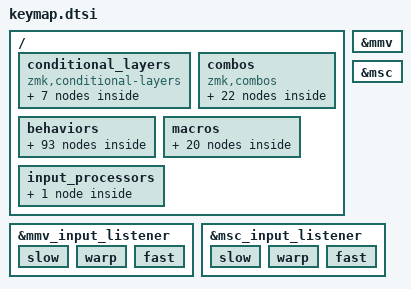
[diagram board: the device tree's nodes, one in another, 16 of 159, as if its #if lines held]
//////////////////////////////////////////////////////////////////////////////
//
// Kinesis Advantage 360 Pro - Keymap Behaviors, Combos, and Macros
//
// Ported from sunaku's Glove80 keymap v52 "Glorious Engrammer"
// https://github.com/sunaku/glove80-keymaps
//
// This file is #include'd by adv360.keymap after positions.h and layer defs.
// LEFT_HAND_KEYS, RIGHT_HAND_KEYS, and *_KEY aliases are in positions.h.
//
//////////////////////////////////////////////////////////////////////////////

//
// NOTE: Use the many #define settings below to customize this keymap!
//
#ifndef OPERATING_SYSTEM
  #define OPERATING_SYSTEM 'L' // choose 'L'inux, 'M'acOS, or 'W'indows
#endif
#ifndef DIFFICULTY_LEVEL
  #define DIFFICULTY_LEVEL  0  // 0:custom, 1:easy -> 5:hard (see below)
#endif
#define ENABLE_MOUSE_KEYS    // requires CONFIG_ZMK_POINTING=y in defconfig
//#define ENFORCE_BILATERAL  // cancels single-handed home row mod+tap
//#define SPACE_FORGIVENESS  // allow lingering taps on the space bar
//#define THUMB_FORGIVENESS  // allow lingering taps on the thumb keys
//#define SHIFT_FORGIVENESS  // requires v24.08-beta or newer firmware
//#define NATURAL_SCROLLING  // supports "natural scrolling" in macOS
//#define WORLD_USE_COMPOSE  // use native Compose in place of Unicode
//#define WORLD_HOST_AZERTY  // host computer is set to AZERTY locale
//#define WORLD_SHIFT_NUMBER // apply Shift to type number row digits
// TIP: Add more setting overrides here instead of editing them below.

//
// OPERATING_SYSTEM defines which operating system you intend to use
// with this keymap, because shortcuts vary across operating systems.
//
#if OPERATING_SYSTEM == 'M'
  #define _C      LG
  #define _A_TAB  LGUI
  #define _G_TAB  LALT
  #define _REDO   LG(LS(Z))
  #define _POWER  K_POWER
  #define _WORD   LA
  #define _HOME   LG(LEFT)
  #define _END    LG(RIGHT)
  #define _EMOJI  LG(LC(SPACE))
  #define _FILES  LS(LA(M))
  #define _GLOBE  GLOBE
#else
  #define _C      LC
  #define _A_TAB  LALT
  #define _G_TAB  LGUI
  #define _REDO   LC(Y)
  #define _POWER  C_POWER
  #define _WORD   LC
  #define _HOME   HOME
  #define _END    END
  #define _EMOJI  LG(DOT)
  #define _FILES  LG(E)
  #define _GLOBE  LGUI
#endif
#define _SLEEP      C_SLEEP
#if OPERATING_SYSTEM == 'W'
  #define _LOCK   LG(L)
#elif OPERATING_SYSTEM == 'M'
  #define _LOCK   _C(LC(Q))
#elif OPERATING_SYSTEM == 'L'
  #define _LOCK   K_LOCK
#endif
#define _UNDO       _C(Z)
#define _CUT        _C(X)
#define _COPY       _C(C)
#define _PASTE      _C(V)
#define _FIND       _C(F)
#define _FIND_NEXT  _C(G)
#define _FIND_PREV  _C(LS(G))

//
// QWERTY base layer alpha key definitions
//
#if defined(LAYER_QWERTY) && LAYER_QWERTY == 0
  #define KEY_LH_C6R1 0
  #define KEY_LH_C5R1 0
  #define KEY_LH_C4R1 0
  #define KEY_LH_C3R1 0
  #define KEY_LH_C2R1 0
  #define KEY_RH_C2R1 0
  #define KEY_RH_C3R1 0
  #define KEY_RH_C4R1 0
  #define KEY_RH_C5R1 0
  #define KEY_RH_C6R1 0
  #define KEY_LH_C6R2 0
  #define KEY_LH_C5R2 N1
  #define KEY_LH_C4R2 N2
  #define KEY_LH_C3R2 N3
  #define KEY_LH_C2R2 N4
  #define KEY_LH_C1R2 N5
  #define KEY_RH_C1R2 N6
  #define KEY_RH_C2R2 N7
  #define KEY_RH_C3R2 N8
  #define KEY_RH_C4R2 N9
  #define KEY_RH_C5R2 N0
  #define KEY_RH_C6R2 0
  #define KEY_LH_C6R3 0
  #define KEY_LH_C5R3 Q
  #define KEY_LH_C4R3 W
  #define KEY_LH_C3R3 E
  #define KEY_LH_C2R3 R
  #define KEY_LH_C1R3 T
  #define KEY_RH_C1R3 Y
  #define KEY_RH_C2R3 U
  #define KEY_RH_C3R3 I
  #define KEY_RH_C4R3 O
  #define KEY_RH_C5R3 P
  #define KEY_RH_C6R3 MINUS
  #define KEY_LH_C6R4 EQUAL
  #define KEY_LH_C5R4 A
  #define KEY_LH_C4R4 S
  #define KEY_LH_C3R4 D
  #define KEY_LH_C2R4 F
  #define KEY_LH_C1R4 G
  #define KEY_RH_C1R4 H
  #define KEY_RH_C2R4 J
  #define KEY_RH_C3R4 K
  #define KEY_RH_C4R4 L
  #define KEY_RH_C5R4 SEMI
  #define KEY_RH_C6R4 SQT
  #define KEY_LH_C6R5 LSFT
  #define KEY_LH_C5R5 Z
  #define KEY_LH_C4R5 X
  #define KEY_LH_C3R5 C
  #define KEY_LH_C2R5 V
  #define KEY_LH_C1R5 B
  #define KEY_LH_T1 ESC
  #define LAY_LH_T1 LAYER_Function
  #define KEY_LH_T2 0
  #define LAY_LH_T2 LAYER_Lower
  #define KEY_LH_T3 PG_UP
  #define KEY_RH_T3 0
  #define KEY_RH_T2 INSERT
  #define LAY_RH_T2 LAYER_Lower
  #define KEY_RH_T1 ENTER
  #define LAY_RH_T1 LAYER_System
  #define KEY_RH_C1R5 N
  #define KEY_RH_C2R5 M
  #define KEY_RH_C3R5 COMMA
  #define KEY_RH_C4R5 DOT
  #define KEY_RH_C5R5 FSLH
  #define KEY_RH_C6R5 RSFT
  #define KEY_LH_C6R6 0
  #define KEY_LH_C5R6 BSLH
  #define KEY_LH_C4R6 LPAR
  #define KEY_LH_C3R6 RPAR
  #define KEY_LH_C2R6 LSFT
  #define LAY_LH_C2R6 LAYER_Emoji
  #define KEY_LH_T4 BACKSPACE
  #define LAY_LH_T4 LAYER_Cursor
  #define KEY_LH_T5 DELETE
  #define LAY_LH_T5 LAYER_Number
  #define KEY_LH_T6 PG_DN
  #define KEY_RH_T6 0
  #define KEY_RH_T5 TAB
  #define LAY_RH_T5 LAYER_Mouse
  #define KEY_RH_T4 SPACE
  #define LAY_RH_T4 LAYER_Symbol
  #define KEY_RH_C2R6 RSFT
  #define LAY_RH_C2R6 LAYER_World
  #define KEY_RH_C3R6 LBKT
  #define KEY_RH_C4R6 RBKT
  #define KEY_RH_C5R6 GRAVE
  #define KEY_RH_C6R6 0
#endif

/ {
conditional_layers {
  compatible = "zmk,conditional-layers";
  #ifdef LAYER_macOS
  #ifdef LAYER_macOS_left
    #ifdef LAYER_Cursor
    if_LAYER_Cursor_then_LAYER_macOS_left {
      if-layers = <LAYER_macOS LAYER_Cursor>;
      then-layer = <LAYER_macOS_left>;
    };
    #endif
    #ifdef LAYER_Number
    if_LAYER_Number_then_LAYER_macOS_left {
      if-layers = <LAYER_macOS LAYER_Number>;
      then-layer = <LAYER_macOS_left>;
    };
    #endif
    #ifdef LAYER_Function
    if_LAYER_Function_then_LAYER_macOS_left {
      if-layers = <LAYER_macOS LAYER_Function>;
      then-layer = <LAYER_macOS_left>;
    };
    #endif
  #endif
  #ifdef LAYER_macOS_right
    #ifdef LAYER_Symbol
    if_LAYER_Symbol_then_LAYER_macOS_right {
      if-layers = <LAYER_macOS LAYER_Symbol>;
      then-layer = <LAYER_macOS_right>;
    };
    #endif
    #ifdef LAYER_Mouse
    if_LAYER_Mouse_then_LAYER_macOS_right {
      if-layers = <LAYER_macOS LAYER_Mouse>;
      then-layer = <LAYER_macOS_right>;
    };
    #endif
    #ifdef LAYER_System
    if_LAYER_System_then_LAYER_macOS_right {
      if-layers = <LAYER_macOS LAYER_System>;
      then-layer = <LAYER_macOS_right>;
    };
    #endif
  #endif
  #ifdef LAYER_macOS_lower
    #ifdef LAYER_Lower
    if_LAYER_Lower_then_LAYER_macOS_lower {
      if-layers = <LAYER_macOS LAYER_Lower>;
      then-layer = <LAYER_macOS_lower>;
    };
    #endif
  #endif
  #endif
};

combos {
  compatible = "zmk,combos";

  //
  // COMBO_FIRING_DECAY defines how much time you have left (milliseconds)
  // after pressing the first key in a ZMK combo to finish the whole chord.
  //
  #ifndef COMBO_FIRING_DECAY
  #define COMBO_FIRING_DECAY 50
  #endif

  //
  // SHIFT_FIRING_DECAY defines how much time you have left (milliseconds)
  // after pressing the first key in the one-shot sticky shift ZMK combo
  // (on index finger home + thumb cluster T1) to finish the whole chord.
  //
  #ifndef SHIFT_FIRING_DECAY
  #define SHIFT_FIRING_DECAY 50
  #endif

  // T2+T3

  combo_sticky_globe_left {
    timeout-ms = <COMBO_FIRING_DECAY>;
    key-positions = <POS_LH_T2 POS_LH_T3>;
    bindings = <&sk _GLOBE>;
    layers = <0 1>;
  };

  combo_sticky_globe_right {
    timeout-ms = <COMBO_FIRING_DECAY>;
    key-positions = <POS_RH_T2 POS_RH_T3>;
    bindings = <&sk _GLOBE>;
    layers = <0 1>;
  };

  // T1+T2

  combo_sticky_altgr_left {
    timeout-ms = <COMBO_FIRING_DECAY>;
    key-positions = <POS_LH_T1 POS_LH_T2>;
    bindings = <&sk RALT>;
    layers = <0 1>;
  };

  combo_sticky_altgr_right {
    timeout-ms = <COMBO_FIRING_DECAY>;
    key-positions = <POS_RH_T1 POS_RH_T2>;
    bindings = <&sk RALT>;
    layers = <0 1>;
  };

  // T1+T4
  #if defined(_A_TAB) && defined(LAYER_Cursor)
  combo_alt_tab_switcher_left {
    timeout-ms = <COMBO_FIRING_DECAY>;
    key-positions = <POS_LH_T1 POS_LH_T4>;
    bindings = <&mod_tab_chord _A_TAB LAYER_Cursor>;
    layers = <0 1>;
  };
  #endif

  combo_hyper_GACS_right {
    timeout-ms = <COMBO_FIRING_DECAY>;
    key-positions = <POS_RH_T1 POS_RH_T4>;
    bindings = <&kp LG(LA(LC(LSHFT)))>;
    layers = <0 1>;
  };

  // T3+T6
  #if defined(_G_TAB) && defined(LAYER_Cursor)
  combo_win_tab_switcher_left {
    timeout-ms = <COMBO_FIRING_DECAY>;
    key-positions = <POS_LH_T3 POS_LH_T6>;
    bindings = <&mod_tab_chord _G_TAB LAYER_Cursor>;
    layers = <0 1>;
  };
  #endif

  combo_turbo_CS_right {
    timeout-ms = <COMBO_FIRING_DECAY>;
    key-positions = <POS_RH_T3 POS_RH_T6>;
    bindings = <&kp LC(LSHFT)>;
    layers = <0 1>;
  };

  // T2+T5

  combo_ctrl_tab_switcher_left {
    timeout-ms = <COMBO_FIRING_DECAY>;
    key-positions = <POS_LH_T2 POS_LH_T5>;
    bindings = <&mod_tab_chord LCTL LAYER_Cursor>;
    layers = <0 1>;
  };

  combo_meh_ACS_right {
    timeout-ms = <COMBO_FIRING_DECAY>;
    key-positions = <POS_RH_T2 POS_RH_T5>;
    bindings = <&kp LA(LC(LSHFT))>;
    layers = <0 1>;
  };

  // T1+T5

  combo_sticky_shift_left {
    timeout-ms = <SHIFT_FIRING_DECAY>;
    key-positions = <POS_LH_T1 POS_LH_T5>;
    bindings = <&sticky_key_modtap LSFT LSFT>;
    layers = <0 1 2>;
  };

  combo_sticky_shift_right {
    timeout-ms = <SHIFT_FIRING_DECAY>;
    key-positions = <POS_RH_T1 POS_RH_T5>;
    bindings = <&sticky_key_modtap RSFT RSFT>;
    layers = <0 1 2>;
  };

  // T4+T5

  combo_caps_word_left {
    timeout-ms = <COMBO_FIRING_DECAY>;
    key-positions = <POS_LH_T4 POS_LH_T5>;
    bindings = <&caps_word>;
    layers = <0 1 2>;
  };

  combo_caps_word_right {
    timeout-ms = <COMBO_FIRING_DECAY>;
    key-positions = <POS_RH_T4 POS_RH_T5>;
    bindings = <&caps_word>;
    layers = <0 1 2>;
  };

  // T2+T6

  combo_caps_lock_left {
    timeout-ms = <COMBO_FIRING_DECAY>;
    key-positions = <POS_LH_T2 POS_LH_T6>;
    bindings = <&kp CAPSLOCK>;
    layers = <0 1 2>;
  };

  combo_caps_lock_right {
    timeout-ms = <COMBO_FIRING_DECAY>;
    key-positions = <POS_RH_T2 POS_RH_T6>;
    bindings = <&kp CAPSLOCK>;
    layers = <0 1 2>;
  };

  // T5+T6
  #ifdef LAYER_Typing
  combo_typing_layer_access_left {
    timeout-ms = <COMBO_FIRING_DECAY>;
    key-positions = <POS_LH_T5 POS_LH_T6>;
    bindings = <&mo LAYER_Typing>;
    layers = <0 1 2 3 4 5 6 7 8 9 10 11 12 13 14 15 16 17 18 19 20 21 22>;
  };

  combo_typing_layer_access_right {
    timeout-ms = <COMBO_FIRING_DECAY>;
    key-positions = <POS_RH_T5 POS_RH_T6>;
    bindings = <&mo LAYER_Typing>;
    layers = <0 1 2 3 4 5 6 7 8 9 10 11 12 13 14 15 16 17 18 19 20 21 22>;
  };
  #endif

  // C1R5+C2R6
  #ifdef LAYER_Gaming
  combo_gaming_layer_toggle {
    timeout-ms = <COMBO_FIRING_DECAY>;
    key-positions = <POS_LH_C1R5 POS_LH_C2R6>;
    bindings = <&tog LAYER_Gaming>;
    layers = <0 LAYER_Gaming
      #ifdef LAYER_macOS
      LAYER_macOS
      #endif
    >;
  };
  #endif
  #ifdef LAYER_Typing
  combo_typing_layer_toggle {
    timeout-ms = <COMBO_FIRING_DECAY>;
    key-positions = <POS_RH_C1R5 POS_RH_C2R6>;
    bindings = <&tog LAYER_Typing>;
    layers = <0 LAYER_Typing
      #ifdef LAYER_macOS
      LAYER_macOS
      #endif
    >;
  };
  #endif

  // T1+T2+T3

  combo_sticky_base_layer_reset_left {
    timeout-ms = <COMBO_FIRING_DECAY>;
    key-positions = <POS_LH_T1 POS_LH_T2 POS_LH_T3>;
    bindings = <&to 0>;
    layers = <0 1 2 3 4 5 6 7 8 9 10 11 12 13 14 15 16 17 18 19 20 21 22>;
  };

  combo_sticky_base_layer_reset_right {
    timeout-ms = <COMBO_FIRING_DECAY>;
    key-positions = <POS_RH_T1 POS_RH_T2 POS_RH_T3>;
    bindings = <&to 0>;
    layers = <0 1 2 3 4 5 6 7 8 9 10 11 12 13 14 15 16 17 18 19 20 21 22>;
  };

};

behaviors {

  //////////////////////////////////////////////////////////////////////////
  //
  // Miryoku layers and home row mods (ported from my QMK endgame)
  // - https://sunaku.github.io/home-row-mods.html#porting-to-zmk
  // - https://github.com/urob/zmk-config#timeless-homerow-mods
  //
  //////////////////////////////////////////////////////////////////////////

  //
  // DIFFICULTY_LEVEL specifies your level of expertise with this keymap.
  // It's meant to help newcomers gradually work their way up to mastery.
  //
  // #define DIFFICULTY_LEVEL 1 // novice (500ms)
  // #define DIFFICULTY_LEVEL 2 // slower (400ms)
  // #define DIFFICULTY_LEVEL 3 // normal (300ms)
  // #define DIFFICULTY_LEVEL 4 // faster (200ms)
  // #define DIFFICULTY_LEVEL 5 // expert (100ms)
  //
  // You can disable this setting by omitting it or assigning a `0` zero,
  // in which case it will default to my personal set of time thresholds.
  //
  // #define DIFFICULTY_LEVEL 0 // sunaku (150ms)
  //
  // No matter what difficulty level you choose, you can always override
  // any settings in this keymap at the beginning of this configuration.
  //
  #ifdef DIFFICULTY_LEVEL
    #if DIFFICULTY_LEVEL > 0 && DIFFICULTY_LEVEL < 6
      #ifndef TAPPING_RESOLUTION
        #define TAPPING_RESOLUTION ((6 - DIFFICULTY_LEVEL) * 100)
      #endif
    #endif
  #endif

  //
  // TAPPING_RESOLUTION specifies the maximum speed at which the keyboard
  // confuses your taps as being holds when you type on home row mod keys.
  // When you lower this value, the same confusion should still occur; but
  // when you raise this value, you should be able to type normally again.
  //
  #ifndef TAPPING_RESOLUTION
  #define TAPPING_RESOLUTION 150
  #endif

  //
  // ENFORCE_BILATERAL cancels out single-handed home row mods activation by
  // releasing any currently pressed mods and replacing them with plain taps.
  //
  // NOTE: You may still encounter "flashing mods" where an operating system
  // action is triggered by the release of mods, such as LGUI which launches
  // the Windows Start Menu and LALT which opens the Microsoft Office Ribbon.
  //
  //#define ENFORCE_BILATERAL

  //
  // SHIFT_FORGIVENESS taps when home row shift is merely held and released,
  // without any other key having been tapped while the shift was held down.
  // For example, suppose you hold a home row shift key and, before pressing
  // another key, you suddenly decide that you don't want the shift anymore:
  //
  // <1> If this setting is enabled, the underlying tap behavior is triggered
  //     to type a single character when you release that home row shift key.
  //
  // <2> Otherwise, nothing happens when you release that home row shift key.
  //
  // This requires the "hold-while-undecided" ZMK feature in a beta firmware:
  // please select "v24.08-beta1" or newer from the drop-down menu located at
  // Glove80 Layout Editor > Settings > Advanced Settings > Firmware Version.
  //
  // CAUTION: This can interfere with mod-click mouse usage where you hold a
  // home row shift key and perform mouse actions (move, click, drag & drop):
  // when you release that home row shift key, its underlying character would
  // be typed, potentially triggering an unexpected action on your selection!
  // To prevent the underlying character from being typed, press another key
  // (such as a dedicated shift key, a neighboring home row mod key, or even
  // a layer access key) before you release the original home row shift key.
  //
  // NOTE: You may potentially encounter "flashing mods" where an application
  // or operating system action is triggered by a standalone tap of a shift,
  // but this is unlikely as people regularly tap shift without consequence.
  //
  //#define SHIFT_FORGIVENESS

  //
  // THUMB_FORGIVENESS taps when a thumb layer access key is merely held and
  // released, without any other key having been tapped while thumb was held.
  // For example, suppose you hold the cursor layer key and, before pressing
  // another key, you suddenly decide that you don't want the layer anymore:
  //
  // <1> If this setting is enabled, the underlying tap behavior is triggered
  //     to type a single character when you release that layer access key.
  //
  // <2> Otherwise, nothing happens when you release that layer access key.
  //
  // NOTE: This setting interferes with (and effectively disables) per-key
  // RGB indicators (PR30) for layers accessed via thumb layer access keys.
  //
  //#define THUMB_FORGIVENESS

  //
  // SPACE_FORGIVENESS taps when the symbol layer access key is merely held
  // and released, without any symbol been tapped while the access was held.
  // For example, suppose you hold the symbol layer key and, before pressing
  // another key, you suddenly decide that you don't want the layer anymore:
  //
  // <1> If this setting is enabled, the underlying tap behavior is triggered
  //     to type a single character when you release that layer access key.
  //
  // <2> Otherwise, nothing happens when you release that layer access key.
  //
  // NOTE: This setting interferes with (and effectively disables) per-key
  // RGB indicators (PR30) for layers accessed via thumb layer access keys.
  //
  //#define SPACE_FORGIVENESS
  #ifdef SPACE_FORGIVENESS
  #ifndef SPACE_HOLDING_TYPE
  #define SPACE_HOLDING_TYPE "tap-preferred"
  #endif
  #endif

  //
  // The *_FINGER_MOD specify which modifiers are used by home row mod keys.
  // Here, we use Miryoku's "GACS" (Win, Alt, Ctrl, Shift) order by default,
  // unless OPERATING_SYSTEM is macOS, in which case Win & Ctrl are swapped,
  // unless MACOS_USE_GACS is also defined to suppress that Win & Ctrl swap.
  //
  #ifndef PINKY_FINGER_MOD
    #if OPERATING_SYSTEM == 'M' && !defined(MACOS_USE_GACS)
      #define PINKY_FINGER_MOD LCTL
    #else
      #define PINKY_FINGER_MOD LGUI
    #endif
  #endif
  #ifndef RINGY_FINGER_MOD
  #define RINGY_FINGER_MOD LALT
  #endif
  #ifndef MIDDY_FINGER_MOD
    #if OPERATING_SYSTEM == 'M' && !defined(MACOS_USE_GACS)
      #define MIDDY_FINGER_MOD LGUI
    #else
      #define MIDDY_FINGER_MOD LCTL
    #endif
  #endif
  #ifndef INDEX_FINGER_MOD
  #define INDEX_FINGER_MOD LSFT
  #endif
  //
  // The following settings let you configure mods individually, per finger:
  //
  #ifndef LEFT_PINKY_MOD
  #define LEFT_PINKY_MOD PINKY_FINGER_MOD
  #endif
  #ifndef RIGHT_PINKY_MOD
  #define RIGHT_PINKY_MOD PINKY_FINGER_MOD
  #endif
  #ifndef LEFT_RINGY_MOD
  #define LEFT_RINGY_MOD RINGY_FINGER_MOD
  #endif
  #ifndef RIGHT_RINGY_MOD
  #define RIGHT_RINGY_MOD RINGY_FINGER_MOD
  #endif
  #ifndef LEFT_MIDDY_MOD
  #define LEFT_MIDDY_MOD MIDDY_FINGER_MOD
  #endif
  #ifndef RIGHT_MIDDY_MOD
  #define RIGHT_MIDDY_MOD MIDDY_FINGER_MOD
  #endif
  #ifndef LEFT_INDEX_MOD
  #define LEFT_INDEX_MOD INDEX_FINGER_MOD
  #endif
  #ifndef RIGHT_INDEX_MOD
  #define RIGHT_INDEX_MOD INDEX_FINGER_MOD
  #endif

  //
  // HOMEY_HOLDING_TYPE defines the flavor of ZMK hold-tap behavior to use
  // for the pinky, ring, and middle fingers (which are assigned to Super,
  // Alt, and Ctrl respectively in the Miryoku system) on home row keys.
  //
  #ifndef HOMEY_HOLDING_TYPE
  #define HOMEY_HOLDING_TYPE "tap-preferred"
  #endif

  //
  // HOMEY_HOLDING_TIME defines how long you need to hold (milliseconds)
  // home row mod keys in order to send their modifiers to the computer
  // (i.e. "register" them) for mod-click mouse usage (e.g. Ctrl-Click).
  //
  #ifndef HOMEY_HOLDING_TIME
  #define HOMEY_HOLDING_TIME (TAPPING_RESOLUTION + 90)
  #endif
  #ifndef INDEX_HOLDING_TIME
  #define INDEX_HOLDING_TIME (TAPPING_RESOLUTION + 30)
  #endif
  #ifndef MIDDY_HOLDING_TIME
  #define MIDDY_HOLDING_TIME (TAPPING_RESOLUTION + 60)
  #endif
  #ifndef RINGY_HOLDING_TIME
  #define RINGY_HOLDING_TIME (TAPPING_RESOLUTION + 90)
  #endif
  #ifndef PINKY_HOLDING_TIME
  #define PINKY_HOLDING_TIME (TAPPING_RESOLUTION + 120)
  #endif

  //
  // HOMEY_STREAK_DECAY defines how long you need to wait (milliseconds)
  // after typing before you can use home row mods again.  It prevents
  // unintended activation of home row mods when you're actively typing.
  //
  #ifndef HOMEY_STREAK_DECAY
  #define HOMEY_STREAK_DECAY TAPPING_RESOLUTION
  #endif

  //
  // HOMEY_REPEAT_DECAY defines how much time you have left (milliseconds)
  // after tapping a key to hold it again in order to make it auto-repeat.
  //
  #ifndef HOMEY_REPEAT_DECAY
  #define HOMEY_REPEAT_DECAY (TAPPING_RESOLUTION + 150)
  #endif // "tap then hold" for key auto-repeat

  //
  // CHORD_HOLDING_TYPE defines the flavor of ZMK hold-tap behavior to use
  // for chorded home row mods (secondary keypresses in multi-mod chords).
  //
  #ifndef CHORD_HOLDING_TYPE
  #define CHORD_HOLDING_TYPE HOMEY_HOLDING_TYPE
  #endif

  //
  // CHORD_HOLDING_TIME defines how long you need to hold (milliseconds)
  // home row mod keys in order to send their modifiers to the computer
  // (i.e. "register" them) for mod-click mouse usage (e.g. Ctrl-Click).
  // This is specifically for secondary keypresses in multi-mod chords.
  //
  #ifndef CHORD_HOLDING_TIME
  #define CHORD_HOLDING_TIME TAPPING_RESOLUTION
  #endif

  //
  // CHORD_STREAK_DECAY defines how long you need to wait (milliseconds)
  // after typing before you can use home row mods again.  It prevents
  // unintended activation of home row mods when you're actively typing
  // This is specifically for secondary keypresses in multi-mod chords.
  //
  #ifndef CHORD_STREAK_DECAY
  #define CHORD_STREAK_DECAY HOMEY_STREAK_DECAY
  #endif

  //
  // CHORD_REPEAT_DECAY defines how much time you have left (milliseconds)
  // after tapping a key to hold it again in order to make it auto-repeat.
  // This is specifically for secondary keypresses in multi-mod chords.
  //
  #ifndef CHORD_REPEAT_DECAY
  #define CHORD_REPEAT_DECAY HOMEY_REPEAT_DECAY
  #endif

  //
  // INDEX_HOLDING_TYPE defines the flavor of ZMK hold-tap behavior to use
  // for index fingers (which Miryoku assigns to Shift) on home row keys.
  //
  // NOTE: The "tap-preferred" flavor of ZMK hold-tap for index finger keys
  // allows faster activation of the Shift modifier (without having to wait
  // for the modified key to be released as the "balanced" flavor requires).
  //
  #ifndef INDEX_HOLDING_TYPE
  #define INDEX_HOLDING_TYPE "tap-preferred"
  #endif

  //
  // INDEX_STREAK_DECAY defines how long you need to wait (milliseconds)
  // after typing before you can use home row mods again.  It prevents
  // unintended activation of home row mods when you're actively typing.
  //
  #ifndef INDEX_STREAK_DECAY
  #define INDEX_STREAK_DECAY TAPPING_RESOLUTION
  #endif

  //
  // INDEX_REPEAT_DECAY defines how much time you have left (milliseconds)
  // after tapping a key to hold it again in order to make it auto-repeat.
  //
  #ifndef INDEX_REPEAT_DECAY
  #define INDEX_REPEAT_DECAY (TAPPING_RESOLUTION + 150)
  #endif // "tap then hold" for key auto-repeat

  //
  // THUMB_HOLDING_TYPE defines the flavor of ZMK hold-tap behavior to use
  // for the thumbs (which are assigned to 6 layers in the Miryoku system).
  //
  // NOTE: The "balanced" flavor of ZMK hold-tap provides instant modifier
  // activation for the symbol layer (if the tapped symbol key is released
  // while the thumb layer key is still held down) for quicker programming.
  //
  #ifndef THUMB_HOLDING_TYPE
  #define THUMB_HOLDING_TYPE "balanced"
  #endif

  //
  // THUMB_HOLDING_TIME defines how long you need to hold (milliseconds)
  // a thumb key to activate a layer.  Shorter holds are treated as taps.
  //
  #ifndef THUMB_HOLDING_TIME
  #define THUMB_HOLDING_TIME (TAPPING_RESOLUTION + 50)
  #endif

  //
  // THUMB_REPEAT_DECAY defines how much time you have left (milliseconds)
  // after tapping a key to hold it again in order to make it auto-repeat.
  //
  #ifndef THUMB_REPEAT_DECAY
  #define THUMB_REPEAT_DECAY (TAPPING_RESOLUTION + 150)
  #endif // "tap then hold" for key auto-repeat

  //
  // SPACE_HOLDING_TYPE defines the flavor of ZMK hold-tap behavior to use
  // for spacebar (assigned to the right thumb's home position by default).
  //
  #ifndef SPACE_HOLDING_TYPE
  #define SPACE_HOLDING_TYPE THUMB_HOLDING_TYPE
  #endif

  //
  // SPACE_HOLDING_TIME defines how long you need to hold (milliseconds)
  // the space thumb key to activate.  Shorter holds are treated as taps.
  //
  #ifndef SPACE_HOLDING_TIME
  #define SPACE_HOLDING_TIME THUMB_HOLDING_TIME
  #endif

  //
  // SPACE_REPEAT_DECAY defines how much time you have left (milliseconds)
  // after tapping a key to hold it again in order to make it auto-repeat.
  //
  #ifndef SPACE_REPEAT_DECAY
  #define SPACE_REPEAT_DECAY TAPPING_RESOLUTION
  #endif

  //

  //
  // Home row mods with bilateral combinations support
  //
  #ifndef PINKY_HOLDING_TYPE
  #define PINKY_HOLDING_TYPE HOMEY_HOLDING_TYPE
  #endif
  #ifndef PINKY_CHORD_HOLDING_TYPE
  #define PINKY_CHORD_HOLDING_TYPE CHORD_HOLDING_TYPE
  #endif
  #ifndef LEFT_PINKY_CHORD_HOLDING_TYPE
  #define LEFT_PINKY_CHORD_HOLDING_TYPE PINKY_CHORD_HOLDING_TYPE
  #endif
  #ifndef RIGHT_PINKY_CHORD_HOLDING_TYPE
  #define RIGHT_PINKY_CHORD_HOLDING_TYPE PINKY_CHORD_HOLDING_TYPE
  #endif
  #ifndef PINKY_HOLDING_TIME
  #define PINKY_HOLDING_TIME HOMEY_HOLDING_TIME
  #endif
  #ifndef PINKY_CHORD_HOLDING_TIME
  #define PINKY_CHORD_HOLDING_TIME CHORD_HOLDING_TIME
  #endif
  #ifndef LEFT_PINKY_CHORD_HOLDING_TIME
  #define LEFT_PINKY_CHORD_HOLDING_TIME PINKY_CHORD_HOLDING_TIME
  #endif
  #ifndef RIGHT_PINKY_CHORD_HOLDING_TIME
  #define RIGHT_PINKY_CHORD_HOLDING_TIME PINKY_CHORD_HOLDING_TIME
  #endif
  #ifndef PINKY_STREAK_DECAY
  #define PINKY_STREAK_DECAY HOMEY_STREAK_DECAY
  #endif
  #ifndef PINKY_CHORD_STREAK_DECAY
  #define PINKY_CHORD_STREAK_DECAY CHORD_STREAK_DECAY
  #endif
  #ifndef LEFT_PINKY_CHORD_STREAK_DECAY
  #define LEFT_PINKY_CHORD_STREAK_DECAY PINKY_CHORD_STREAK_DECAY
  #endif
  #ifndef RIGHT_PINKY_CHORD_STREAK_DECAY
  #define RIGHT_PINKY_CHORD_STREAK_DECAY PINKY_CHORD_STREAK_DECAY
  #endif
  #ifndef PINKY_REPEAT_DECAY
  #define PINKY_REPEAT_DECAY HOMEY_REPEAT_DECAY
  #endif
  #ifndef PINKY_CHORD_REPEAT_DECAY
  #define PINKY_CHORD_REPEAT_DECAY CHORD_REPEAT_DECAY
  #endif
  #ifndef LEFT_PINKY_CHORD_REPEAT_DECAY
  #define LEFT_PINKY_CHORD_REPEAT_DECAY PINKY_CHORD_REPEAT_DECAY
  #endif
  #ifndef RIGHT_PINKY_CHORD_REPEAT_DECAY
  #define RIGHT_PINKY_CHORD_REPEAT_DECAY PINKY_CHORD_REPEAT_DECAY
  #endif
  #ifndef RINGY_HOLDING_TYPE
  #define RINGY_HOLDING_TYPE HOMEY_HOLDING_TYPE
  #endif
  #ifndef RINGY_CHORD_HOLDING_TYPE
  #define RINGY_CHORD_HOLDING_TYPE CHORD_HOLDING_TYPE
  #endif
  #ifndef LEFT_RINGY_CHORD_HOLDING_TYPE
  #define LEFT_RINGY_CHORD_HOLDING_TYPE RINGY_CHORD_HOLDING_TYPE
  #endif
  #ifndef RIGHT_RINGY_CHORD_HOLDING_TYPE
  #define RIGHT_RINGY_CHORD_HOLDING_TYPE RINGY_CHORD_HOLDING_TYPE
  #endif
  #ifndef RINGY_HOLDING_TIME
  #define RINGY_HOLDING_TIME HOMEY_HOLDING_TIME
  #endif
  #ifndef RINGY_CHORD_HOLDING_TIME
  #define RINGY_CHORD_HOLDING_TIME CHORD_HOLDING_TIME
  #endif
  #ifndef LEFT_RINGY_CHORD_HOLDING_TIME
  #define LEFT_RINGY_CHORD_HOLDING_TIME RINGY_CHORD_HOLDING_TIME
  #endif
  #ifndef RIGHT_RINGY_CHORD_HOLDING_TIME
  #define RIGHT_RINGY_CHORD_HOLDING_TIME RINGY_CHORD_HOLDING_TIME
  #endif
  #ifndef RINGY_STREAK_DECAY
  #define RINGY_STREAK_DECAY HOMEY_STREAK_DECAY
  #endif
  #ifndef RINGY_CHORD_STREAK_DECAY
  #define RINGY_CHORD_STREAK_DECAY CHORD_STREAK_DECAY
  #endif
  #ifndef LEFT_RINGY_CHORD_STREAK_DECAY
  #define LEFT_RINGY_CHORD_STREAK_DECAY RINGY_CHORD_STREAK_DECAY
  #endif
  #ifndef RIGHT_RINGY_CHORD_STREAK_DECAY
  #define RIGHT_RINGY_CHORD_STREAK_DECAY RINGY_CHORD_STREAK_DECAY
  #endif
  #ifndef RINGY_REPEAT_DECAY
  #define RINGY_REPEAT_DECAY HOMEY_REPEAT_DECAY
  #endif
  #ifndef RINGY_CHORD_REPEAT_DECAY
  #define RINGY_CHORD_REPEAT_DECAY CHORD_REPEAT_DECAY
  #endif
  #ifndef LEFT_RINGY_CHORD_REPEAT_DECAY
  #define LEFT_RINGY_CHORD_REPEAT_DECAY RINGY_CHORD_REPEAT_DECAY
  #endif
  #ifndef RIGHT_RINGY_CHORD_REPEAT_DECAY
  #define RIGHT_RINGY_CHORD_REPEAT_DECAY RINGY_CHORD_REPEAT_DECAY
  #endif
  #ifndef MIDDY_HOLDING_TYPE
  #define MIDDY_HOLDING_TYPE HOMEY_HOLDING_TYPE
  #endif
  #ifndef MIDDY_CHORD_HOLDING_TYPE
  #define MIDDY_CHORD_HOLDING_TYPE CHORD_HOLDING_TYPE
  #endif
  #ifndef LEFT_MIDDY_CHORD_HOLDING_TYPE
  #define LEFT_MIDDY_CHORD_HOLDING_TYPE MIDDY_CHORD_HOLDING_TYPE
  #endif
  #ifndef RIGHT_MIDDY_CHORD_HOLDING_TYPE
  #define RIGHT_MIDDY_CHORD_HOLDING_TYPE MIDDY_CHORD_HOLDING_TYPE
  #endif
  #ifndef MIDDY_HOLDING_TIME
  #define MIDDY_HOLDING_TIME HOMEY_HOLDING_TIME
  #endif
  #ifndef MIDDY_CHORD_HOLDING_TIME
  #define MIDDY_CHORD_HOLDING_TIME CHORD_HOLDING_TIME
  #endif
  #ifndef LEFT_MIDDY_CHORD_HOLDING_TIME
  #define LEFT_MIDDY_CHORD_HOLDING_TIME MIDDY_CHORD_HOLDING_TIME
  #endif
  #ifndef RIGHT_MIDDY_CHORD_HOLDING_TIME
  #define RIGHT_MIDDY_CHORD_HOLDING_TIME MIDDY_CHORD_HOLDING_TIME
  #endif
  #ifndef MIDDY_STREAK_DECAY
  #define MIDDY_STREAK_DECAY HOMEY_STREAK_DECAY
  #endif
  #ifndef MIDDY_CHORD_STREAK_DECAY
  #define MIDDY_CHORD_STREAK_DECAY CHORD_STREAK_DECAY
  #endif
  #ifndef LEFT_MIDDY_CHORD_STREAK_DECAY
  #define LEFT_MIDDY_CHORD_STREAK_DECAY MIDDY_CHORD_STREAK_DECAY
  #endif
  #ifndef RIGHT_MIDDY_CHORD_STREAK_DECAY
  #define RIGHT_MIDDY_CHORD_STREAK_DECAY MIDDY_CHORD_STREAK_DECAY
  #endif
  #ifndef MIDDY_REPEAT_DECAY
  #define MIDDY_REPEAT_DECAY HOMEY_REPEAT_DECAY
  #endif
  #ifndef MIDDY_CHORD_REPEAT_DECAY
  #define MIDDY_CHORD_REPEAT_DECAY CHORD_REPEAT_DECAY
  #endif
  #ifndef LEFT_MIDDY_CHORD_REPEAT_DECAY
  #define LEFT_MIDDY_CHORD_REPEAT_DECAY MIDDY_CHORD_REPEAT_DECAY
  #endif
  #ifndef RIGHT_MIDDY_CHORD_REPEAT_DECAY
  #define RIGHT_MIDDY_CHORD_REPEAT_DECAY MIDDY_CHORD_REPEAT_DECAY
  #endif
  #ifndef INDEX_HOLDING_TYPE
  #define INDEX_HOLDING_TYPE HOMEY_HOLDING_TYPE
  #endif
  #ifndef INDEX_CHORD_HOLDING_TYPE
  #define INDEX_CHORD_HOLDING_TYPE CHORD_HOLDING_TYPE
  #endif
  #ifndef LEFT_INDEX_CHORD_HOLDING_TYPE
  #define LEFT_INDEX_CHORD_HOLDING_TYPE INDEX_CHORD_HOLDING_TYPE
  #endif
  #ifndef RIGHT_INDEX_CHORD_HOLDING_TYPE
  #define RIGHT_INDEX_CHORD_HOLDING_TYPE INDEX_CHORD_HOLDING_TYPE
  #endif
  #ifndef INDEX_HOLDING_TIME
  #define INDEX_HOLDING_TIME HOMEY_HOLDING_TIME
  #endif
  #ifndef INDEX_CHORD_HOLDING_TIME
  #define INDEX_CHORD_HOLDING_TIME CHORD_HOLDING_TIME
  #endif
  #ifndef LEFT_INDEX_CHORD_HOLDING_TIME
  #define LEFT_INDEX_CHORD_HOLDING_TIME INDEX_CHORD_HOLDING_TIME
  #endif
  #ifndef RIGHT_INDEX_CHORD_HOLDING_TIME
  #define RIGHT_INDEX_CHORD_HOLDING_TIME INDEX_CHORD_HOLDING_TIME
  #endif
  #ifndef INDEX_STREAK_DECAY
  #define INDEX_STREAK_DECAY HOMEY_STREAK_DECAY
  #endif
  #ifndef INDEX_CHORD_STREAK_DECAY
  #define INDEX_CHORD_STREAK_DECAY CHORD_STREAK_DECAY
  #endif
  #ifndef LEFT_INDEX_CHORD_STREAK_DECAY
  #define LEFT_INDEX_CHORD_STREAK_DECAY INDEX_CHORD_STREAK_DECAY
  #endif
  #ifndef RIGHT_INDEX_CHORD_STREAK_DECAY
  #define RIGHT_INDEX_CHORD_STREAK_DECAY INDEX_CHORD_STREAK_DECAY
  #endif
  #ifndef INDEX_REPEAT_DECAY
  #define INDEX_REPEAT_DECAY HOMEY_REPEAT_DECAY
  #endif
  #ifndef INDEX_CHORD_REPEAT_DECAY
  #define INDEX_CHORD_REPEAT_DECAY CHORD_REPEAT_DECAY
  #endif
  #ifndef LEFT_INDEX_CHORD_REPEAT_DECAY
  #define LEFT_INDEX_CHORD_REPEAT_DECAY INDEX_CHORD_REPEAT_DECAY
  #endif
  #ifndef RIGHT_INDEX_CHORD_REPEAT_DECAY
  #define RIGHT_INDEX_CHORD_REPEAT_DECAY INDEX_CHORD_REPEAT_DECAY
  #endif
  #ifndef LEFT_PINKY_HOLDING_TYPE
  #define LEFT_PINKY_HOLDING_TYPE PINKY_HOLDING_TYPE
  #endif
  #ifndef LEFT_PINKY_HOLDING_TIME
  #define LEFT_PINKY_HOLDING_TIME PINKY_HOLDING_TIME
  #endif
  #ifndef LEFT_PINKY_STREAK_DECAY
  #define LEFT_PINKY_STREAK_DECAY PINKY_STREAK_DECAY
  #endif
  #ifndef LEFT_PINKY_REPEAT_DECAY
  #define LEFT_PINKY_REPEAT_DECAY PINKY_REPEAT_DECAY
  #endif
  left_pinky: homey_left_pinky {
    compatible = "zmk,behavior-hold-tap";
    flavor = LEFT_PINKY_HOLDING_TYPE;
    hold-trigger-key-positions = <RIGHT_HAND_KEYS>;
    hold-trigger-on-release; // wait for other home row mods
    tapping-term-ms = <LEFT_PINKY_HOLDING_TIME>;
    quick-tap-ms = <LEFT_PINKY_REPEAT_DECAY>;
    require-prior-idle-ms = <LEFT_PINKY_STREAK_DECAY>;
    #binding-cells = <2>;
    bindings = <&kp>, <&kp>;
    #ifdef SHIFT_FORGIVENESS
      #if LEFT_PINKY_MOD == LSFT || LEFT_PINKY_MOD == RSFT
        hold-while-undecided; // requires 24.08-beta1 or newer firmware
        retro-tap; // tap on standalone hold
      #endif
    #endif
  };
  left_pinky_bilateral: homey_left_pinky_bilateral {
    compatible = "zmk,behavior-hold-tap";
    flavor = LEFT_PINKY_HOLDING_TYPE;
    hold-trigger-key-positions = <RIGHT_HAND_KEYS>;
    hold-trigger-on-release; // wait for other home row mods
    tapping-term-ms = <LEFT_PINKY_HOLDING_TIME>;
    quick-tap-ms = <LEFT_PINKY_REPEAT_DECAY>;
    require-prior-idle-ms = <LEFT_PINKY_STREAK_DECAY>;
    #binding-cells = <2>;
    bindings = <&left_pinky_hold>, <&kp>;
    #ifdef SHIFT_FORGIVENESS
      #if LEFT_PINKY_MOD == LSFT || LEFT_PINKY_MOD == RSFT
        hold-while-undecided; // requires 24.08-beta1 or newer firmware
        retro-tap; // tap on standalone hold
      #endif
    #endif
  };
  left_pinky_hold: homey_left_pinky_hold {
    compatible = "zmk,behavior-macro-one-param";
    wait-ms = <0>;
    tap-ms = <0>;
    #binding-cells = <1>;
    bindings
      = <&macro_param_1to1>
      , <&macro_press &kp MACRO_PLACEHOLDER>
      #ifdef LAYER_LeftPinky
      , <&macro_press &mo LAYER_LeftPinky>
      #endif
      , <&macro_pause_for_release>
      , <&macro_param_1to1>
      , <&macro_release &kp MACRO_PLACEHOLDER>
      #ifdef LAYER_LeftPinky
      , <&macro_release &mo LAYER_LeftPinky>
      #endif
      ;
  };
  left_pinky_tap: homey_left_pinky_tap {
    compatible = "zmk,behavior-macro-one-param";
    wait-ms = <0>;
    tap-ms = <0>;
    #binding-cells = <1>;
    bindings
      = <&macro_release
          &kp LSFT &kp RSFT
          &kp LALT &kp RALT
          &kp LCTL &kp RCTL
          &kp LGUI &kp RGUI>
      , <&macro_tap &kp LEFT_PINKY_KEY>
      , <&macro_param_1to1>
      , <&macro_tap &kp MACRO_PLACEHOLDER>
      ;
  };
  #define LeftPinky(key, layer_index) LeftPinky_unroll(layer_index) (key)
  #define LeftPinky_unroll(layer_index) LeftPinky_concat(LeftPinky_layer, layer_index)
  #define LeftPinky_concat(prefix, layer_index) prefix ## layer_index
  #ifdef ENFORCE_BILATERAL
    #define left_pinky_layer0_variant left_pinky_bilateral
  #else
    #define left_pinky_layer0_variant left_pinky
  #endif
  #define LeftPinky_layer0(key) left_pinky_layer0_variant LEFT_PINKY_MOD key
  #ifndef RIGHT_PINKY_HOLDING_TYPE
  #define RIGHT_PINKY_HOLDING_TYPE PINKY_HOLDING_TYPE
  #endif
  #ifndef RIGHT_PINKY_HOLDING_TIME
  #define RIGHT_PINKY_HOLDING_TIME PINKY_HOLDING_TIME
  #endif
  #ifndef RIGHT_PINKY_STREAK_DECAY
  #define RIGHT_PINKY_STREAK_DECAY PINKY_STREAK_DECAY
  #endif
  #ifndef RIGHT_PINKY_REPEAT_DECAY
  #define RIGHT_PINKY_REPEAT_DECAY PINKY_REPEAT_DECAY
  #endif
  right_pinky: homey_right_pinky {
    compatible = "zmk,behavior-hold-tap";
    flavor = RIGHT_PINKY_HOLDING_TYPE;
    hold-trigger-key-positions = <LEFT_HAND_KEYS>;
    hold-trigger-on-release; // wait for other home row mods
    tapping-term-ms = <RIGHT_PINKY_HOLDING_TIME>;
    quick-tap-ms = <RIGHT_PINKY_REPEAT_DECAY>;
    require-prior-idle-ms = <RIGHT_PINKY_STREAK_DECAY>;
    #binding-cells = <2>;
    bindings = <&kp>, <&kp>;
    #ifdef SHIFT_FORGIVENESS
      #if RIGHT_PINKY_MOD == LSFT || RIGHT_PINKY_MOD == RSFT
        hold-while-undecided; // requires 24.08-beta1 or newer firmware
        retro-tap; // tap on standalone hold
      #endif
    #endif
  };
  right_pinky_bilateral: homey_right_pinky_bilateral {
    compatible = "zmk,behavior-hold-tap";
    flavor = RIGHT_PINKY_HOLDING_TYPE;
    hold-trigger-key-positions = <LEFT_HAND_KEYS>;
    hold-trigger-on-release; // wait for other home row mods
    tapping-term-ms = <RIGHT_PINKY_HOLDING_TIME>;
    quick-tap-ms = <RIGHT_PINKY_REPEAT_DECAY>;
    require-prior-idle-ms = <RIGHT_PINKY_STREAK_DECAY>;
    #binding-cells = <2>;
    bindings = <&right_pinky_hold>, <&kp>;
    #ifdef SHIFT_FORGIVENESS
      #if RIGHT_PINKY_MOD == LSFT || RIGHT_PINKY_MOD == RSFT
        hold-while-undecided; // requires 24.08-beta1 or newer firmware
        retro-tap; // tap on standalone hold
      #endif
    #endif
  };
  right_pinky_hold: homey_right_pinky_hold {
    compatible = "zmk,behavior-macro-one-param";
    wait-ms = <0>;
    tap-ms = <0>;
    #binding-cells = <1>;
    bindings
      = <&macro_param_1to1>
      , <&macro_press &kp MACRO_PLACEHOLDER>
      #ifdef LAYER_RightPinky
      , <&macro_press &mo LAYER_RightPinky>
      #endif
      , <&macro_pause_for_release>
      , <&macro_param_1to1>
      , <&macro_release &kp MACRO_PLACEHOLDER>
      #ifdef LAYER_RightPinky
      , <&macro_release &mo LAYER_RightPinky>
      #endif
      ;
  };
  right_pinky_tap: homey_right_pinky_tap {
    compatible = "zmk,behavior-macro-one-param";
    wait-ms = <0>;
    tap-ms = <0>;
    #binding-cells = <1>;
    bindings
      = <&macro_release
          &kp LSFT &kp RSFT
          &kp LALT &kp RALT
          &kp LCTL &kp RCTL
          &kp LGUI &kp RGUI>
      , <&macro_tap &kp RIGHT_PINKY_KEY>
      , <&macro_param_1to1>
      , <&macro_tap &kp MACRO_PLACEHOLDER>
      ;
  };
  #define RightPinky(key, layer_index) RightPinky_unroll(layer_index) (key)
  #define RightPinky_unroll(layer_index) RightPinky_concat(RightPinky_layer, layer_index)
  #define RightPinky_concat(prefix, layer_index) prefix ## layer_index
  #ifdef ENFORCE_BILATERAL
    #define right_pinky_layer0_variant right_pinky_bilateral
  #else
    #define right_pinky_layer0_variant right_pinky
  #endif
  #define RightPinky_layer0(key) right_pinky_layer0_variant RIGHT_PINKY_MOD key
  #ifndef LEFT_RINGY_HOLDING_TYPE
  #define LEFT_RINGY_HOLDING_TYPE RINGY_HOLDING_TYPE
  #endif
  #ifndef LEFT_RINGY_HOLDING_TIME
  #define LEFT_RINGY_HOLDING_TIME RINGY_HOLDING_TIME
  #endif
  #ifndef LEFT_RINGY_STREAK_DECAY
  #define LEFT_RINGY_STREAK_DECAY RINGY_STREAK_DECAY
  #endif
  #ifndef LEFT_RINGY_REPEAT_DECAY
  #define LEFT_RINGY_REPEAT_DECAY RINGY_REPEAT_DECAY
  #endif
  left_ringy: homey_left_ringy {
    compatible = "zmk,behavior-hold-tap";
    flavor = LEFT_RINGY_HOLDING_TYPE;
    hold-trigger-key-positions = <RIGHT_HAND_KEYS>;
    hold-trigger-on-release; // wait for other home row mods
    tapping-term-ms = <LEFT_RINGY_HOLDING_TIME>;
    quick-tap-ms = <LEFT_RINGY_REPEAT_DECAY>;
    require-prior-idle-ms = <LEFT_RINGY_STREAK_DECAY>;
    #binding-cells = <2>;
    bindings = <&kp>, <&kp>;
    #ifdef SHIFT_FORGIVENESS
      #if LEFT_RINGY_MOD == LSFT || LEFT_RINGY_MOD == RSFT
        hold-while-undecided; // requires 24.08-beta1 or newer firmware
        retro-tap; // tap on standalone hold
      #endif
    #endif
  };
  left_ringy_bilateral: homey_left_ringy_bilateral {
    compatible = "zmk,behavior-hold-tap";
    flavor = LEFT_RINGY_HOLDING_TYPE;
    hold-trigger-key-positions = <RIGHT_HAND_KEYS>;
    hold-trigger-on-release; // wait for other home row mods
    tapping-term-ms = <LEFT_RINGY_HOLDING_TIME>;
    quick-tap-ms = <LEFT_RINGY_REPEAT_DECAY>;
    require-prior-idle-ms = <LEFT_RINGY_STREAK_DECAY>;
    #binding-cells = <2>;
    bindings = <&left_ringy_hold>, <&kp>;
    #ifdef SHIFT_FORGIVENESS
      #if LEFT_RINGY_MOD == LSFT || LEFT_RINGY_MOD == RSFT
        hold-while-undecided; // requires 24.08-beta1 or newer firmware
        retro-tap; // tap on standalone hold
      #endif
    #endif
  };
  left_ringy_hold: homey_left_ringy_hold {
    compatible = "zmk,behavior-macro-one-param";
    wait-ms = <0>;
    tap-ms = <0>;
    #binding-cells = <1>;
    bindings
      = <&macro_param_1to1>
      , <&macro_press &kp MACRO_PLACEHOLDER>
      #ifdef LAYER_LeftRingy
      , <&macro_press &mo LAYER_LeftRingy>
      #endif
      , <&macro_pause_for_release>
      , <&macro_param_1to1>
      , <&macro_release &kp MACRO_PLACEHOLDER>
      #ifdef LAYER_LeftRingy
      , <&macro_release &mo LAYER_LeftRingy>
      #endif
      ;
  };
  left_ringy_tap: homey_left_ringy_tap {
    compatible = "zmk,behavior-macro-one-param";
    wait-ms = <0>;
    tap-ms = <0>;
    #binding-cells = <1>;
    bindings
      = <&macro_release
          &kp LSFT &kp RSFT
          &kp LALT &kp RALT
          &kp LCTL &kp RCTL
          &kp LGUI &kp RGUI>
      , <&macro_tap &kp LEFT_RINGY_KEY>
      , <&macro_param_1to1>
      , <&macro_tap &kp MACRO_PLACEHOLDER>
      ;
  };
  #define LeftRingy(key, layer_index) LeftRingy_unroll(layer_index) (key)
  #define LeftRingy_unroll(layer_index) LeftRingy_concat(LeftRingy_layer, layer_index)
  #define LeftRingy_concat(prefix, layer_index) prefix ## layer_index
  #ifdef ENFORCE_BILATERAL
    #define left_ringy_layer0_variant left_ringy_bilateral
  #else
    #define left_ringy_layer0_variant left_ringy
  #endif
  #define LeftRingy_layer0(key) left_ringy_layer0_variant LEFT_RINGY_MOD key
  #ifndef RIGHT_RINGY_HOLDING_TYPE
  #define RIGHT_RINGY_HOLDING_TYPE RINGY_HOLDING_TYPE
  #endif
  #ifndef RIGHT_RINGY_HOLDING_TIME
  #define RIGHT_RINGY_HOLDING_TIME RINGY_HOLDING_TIME
  #endif
  #ifndef RIGHT_RINGY_STREAK_DECAY
  #define RIGHT_RINGY_STREAK_DECAY RINGY_STREAK_DECAY
  #endif
  #ifndef RIGHT_RINGY_REPEAT_DECAY
  #define RIGHT_RINGY_REPEAT_DECAY RINGY_REPEAT_DECAY
  #endif
  right_ringy: homey_right_ringy {
    compatible = "zmk,behavior-hold-tap";
    flavor = RIGHT_RINGY_HOLDING_TYPE;
    hold-trigger-key-positions = <LEFT_HAND_KEYS>;
    hold-trigger-on-release; // wait for other home row mods
    tapping-term-ms = <RIGHT_RINGY_HOLDING_TIME>;
    quick-tap-ms = <RIGHT_RINGY_REPEAT_DECAY>;
    require-prior-idle-ms = <RIGHT_RINGY_STREAK_DECAY>;
    #binding-cells = <2>;
    bindings = <&kp>, <&kp>;
    #ifdef SHIFT_FORGIVENESS
      #if RIGHT_RINGY_MOD == LSFT || RIGHT_RINGY_MOD == RSFT
        hold-while-undecided; // requires 24.08-beta1 or newer firmware
        retro-tap; // tap on standalone hold
      #endif
    #endif
  };
  right_ringy_bilateral: homey_right_ringy_bilateral {
    compatible = "zmk,behavior-hold-tap";
    flavor = RIGHT_RINGY_HOLDING_TYPE;
    hold-trigger-key-positions = <LEFT_HAND_KEYS>;
    hold-trigger-on-release; // wait for other home row mods
    tapping-term-ms = <RIGHT_RINGY_HOLDING_TIME>;
    quick-tap-ms = <RIGHT_RINGY_REPEAT_DECAY>;
    require-prior-idle-ms = <RIGHT_RINGY_STREAK_DECAY>;
    #binding-cells = <2>;
    bindings = <&right_ringy_hold>, <&kp>;
    #ifdef SHIFT_FORGIVENESS
      #if RIGHT_RINGY_MOD == LSFT || RIGHT_RINGY_MOD == RSFT
        hold-while-undecided; // requires 24.08-beta1 or newer firmware
        retro-tap; // tap on standalone hold
      #endif
    #endif
  };
  right_ringy_hold: homey_right_ringy_hold {
    compatible = "zmk,behavior-macro-one-param";
    wait-ms = <0>;
    tap-ms = <0>;
    #binding-cells = <1>;
    bindings
      = <&macro_param_1to1>
      , <&macro_press &kp MACRO_PLACEHOLDER>
      #ifdef LAYER_RightRingy
      , <&macro_press &mo LAYER_RightRingy>
      #endif
      , <&macro_pause_for_release>
      , <&macro_param_1to1>
      , <&macro_release &kp MACRO_PLACEHOLDER>
      #ifdef LAYER_RightRingy
      , <&macro_release &mo LAYER_RightRingy>
      #endif
      ;
  };
  right_ringy_tap: homey_right_ringy_tap {
    compatible = "zmk,behavior-macro-one-param";
    wait-ms = <0>;
    tap-ms = <0>;
    #binding-cells = <1>;
    bindings
      = <&macro_release
          &kp LSFT &kp RSFT
          &kp LALT &kp RALT
          &kp LCTL &kp RCTL
          &kp LGUI &kp RGUI>
      , <&macro_tap &kp RIGHT_RINGY_KEY>
      , <&macro_param_1to1>
      , <&macro_tap &kp MACRO_PLACEHOLDER>
      ;
  };
  #define RightRingy(key, layer_index) RightRingy_unroll(layer_index) (key)
  #define RightRingy_unroll(layer_index) RightRingy_concat(RightRingy_layer, layer_index)
  #define RightRingy_concat(prefix, layer_index) prefix ## layer_index
  #ifdef ENFORCE_BILATERAL
    #define right_ringy_layer0_variant right_ringy_bilateral
  #else
    #define right_ringy_layer0_variant right_ringy
  #endif
  #define RightRingy_layer0(key) right_ringy_layer0_variant RIGHT_RINGY_MOD key
  #ifndef LEFT_MIDDY_HOLDING_TYPE
  #define LEFT_MIDDY_HOLDING_TYPE MIDDY_HOLDING_TYPE
  #endif
  #ifndef LEFT_MIDDY_HOLDING_TIME
  #define LEFT_MIDDY_HOLDING_TIME MIDDY_HOLDING_TIME
  #endif
  #ifndef LEFT_MIDDY_STREAK_DECAY
  #define LEFT_MIDDY_STREAK_DECAY MIDDY_STREAK_DECAY
  #endif
  #ifndef LEFT_MIDDY_REPEAT_DECAY
  #define LEFT_MIDDY_REPEAT_DECAY MIDDY_REPEAT_DECAY
  #endif
  left_middy: homey_left_middy {
    compatible = "zmk,behavior-hold-tap";
    flavor = LEFT_MIDDY_HOLDING_TYPE;
    hold-trigger-key-positions = <RIGHT_HAND_KEYS>;
    hold-trigger-on-release; // wait for other home row mods
    tapping-term-ms = <LEFT_MIDDY_HOLDING_TIME>;
    quick-tap-ms = <LEFT_MIDDY_REPEAT_DECAY>;
    require-prior-idle-ms = <LEFT_MIDDY_STREAK_DECAY>;
    #binding-cells = <2>;
    bindings = <&kp>, <&kp>;
    #ifdef SHIFT_FORGIVENESS
      #if LEFT_MIDDY_MOD == LSFT || LEFT_MIDDY_MOD == RSFT
        hold-while-undecided; // requires 24.08-beta1 or newer firmware
        retro-tap; // tap on standalone hold
      #endif
    #endif
  };
  left_middy_bilateral: homey_left_middy_bilateral {
    compatible = "zmk,behavior-hold-tap";
    flavor = LEFT_MIDDY_HOLDING_TYPE;
    hold-trigger-key-positions = <RIGHT_HAND_KEYS>;
    hold-trigger-on-release; // wait for other home row mods
    tapping-term-ms = <LEFT_MIDDY_HOLDING_TIME>;
    quick-tap-ms = <LEFT_MIDDY_REPEAT_DECAY>;
    require-prior-idle-ms = <LEFT_MIDDY_STREAK_DECAY>;
    #binding-cells = <2>;
    bindings = <&left_middy_hold>, <&kp>;
    #ifdef SHIFT_FORGIVENESS
      #if LEFT_MIDDY_MOD == LSFT || LEFT_MIDDY_MOD == RSFT
        hold-while-undecided; // requires 24.08-beta1 or newer firmware
        retro-tap; // tap on standalone hold
      #endif
    #endif
  };
  left_middy_hold: homey_left_middy_hold {
    compatible = "zmk,behavior-macro-one-param";
    wait-ms = <0>;
    tap-ms = <0>;
    #binding-cells = <1>;
    bindings
      = <&macro_param_1to1>
      , <&macro_press &kp MACRO_PLACEHOLDER>
      #ifdef LAYER_LeftMiddy
      , <&macro_press &mo LAYER_LeftMiddy>
      #endif
      , <&macro_pause_for_release>
      , <&macro_param_1to1>
      , <&macro_release &kp MACRO_PLACEHOLDER>
      #ifdef LAYER_LeftMiddy
      , <&macro_release &mo LAYER_LeftMiddy>
      #endif
      ;
  };
  left_middy_tap: homey_left_middy_tap {
    compatible = "zmk,behavior-macro-one-param";
    wait-ms = <0>;
    tap-ms = <0>;
    #binding-cells = <1>;
    bindings
      = <&macro_release
          &kp LSFT &kp RSFT
          &kp LALT &kp RALT
          &kp LCTL &kp RCTL
          &kp LGUI &kp RGUI>
      , <&macro_tap &kp LEFT_MIDDY_KEY>
      , <&macro_param_1to1>
      , <&macro_tap &kp MACRO_PLACEHOLDER>
      ;
  };
  #define LeftMiddy(key, layer_index) LeftMiddy_unroll(layer_index) (key)
  #define LeftMiddy_unroll(layer_index) LeftMiddy_concat(LeftMiddy_layer, layer_index)
  #define LeftMiddy_concat(prefix, layer_index) prefix ## layer_index
  #ifdef ENFORCE_BILATERAL
    #define left_middy_layer0_variant left_middy_bilateral
  #else
    #define left_middy_layer0_variant left_middy
  #endif
  #define LeftMiddy_layer0(key) left_middy_layer0_variant LEFT_MIDDY_MOD key
  #ifndef RIGHT_MIDDY_HOLDING_TYPE
  #define RIGHT_MIDDY_HOLDING_TYPE MIDDY_HOLDING_TYPE
  #endif
  #ifndef RIGHT_MIDDY_HOLDING_TIME
  #define RIGHT_MIDDY_HOLDING_TIME MIDDY_HOLDING_TIME
  #endif
  #ifndef RIGHT_MIDDY_STREAK_DECAY
  #define RIGHT_MIDDY_STREAK_DECAY MIDDY_STREAK_DECAY
  #endif
  #ifndef RIGHT_MIDDY_REPEAT_DECAY
  #define RIGHT_MIDDY_REPEAT_DECAY MIDDY_REPEAT_DECAY
  #endif
  right_middy: homey_right_middy {
    compatible = "zmk,behavior-hold-tap";
    flavor = RIGHT_MIDDY_HOLDING_TYPE;
    hold-trigger-key-positions = <LEFT_HAND_KEYS>;
    hold-trigger-on-release; // wait for other home row mods
    tapping-term-ms = <RIGHT_MIDDY_HOLDING_TIME>;
    quick-tap-ms = <RIGHT_MIDDY_REPEAT_DECAY>;
    require-prior-idle-ms = <RIGHT_MIDDY_STREAK_DECAY>;
    #binding-cells = <2>;
    bindings = <&kp>, <&kp>;
    #ifdef SHIFT_FORGIVENESS
      #if RIGHT_MIDDY_MOD == LSFT || RIGHT_MIDDY_MOD == RSFT
        hold-while-undecided; // requires 24.08-beta1 or newer firmware
        retro-tap; // tap on standalone hold
      #endif
    #endif
  };
  right_middy_bilateral: homey_right_middy_bilateral {
    compatible = "zmk,behavior-hold-tap";
    flavor = RIGHT_MIDDY_HOLDING_TYPE;
    hold-trigger-key-positions = <LEFT_HAND_KEYS>;
    hold-trigger-on-release; // wait for other home row mods
    tapping-term-ms = <RIGHT_MIDDY_HOLDING_TIME>;
    quick-tap-ms = <RIGHT_MIDDY_REPEAT_DECAY>;
    require-prior-idle-ms = <RIGHT_MIDDY_STREAK_DECAY>;
    #binding-cells = <2>;
    bindings = <&right_middy_hold>, <&kp>;
    #ifdef SHIFT_FORGIVENESS
      #if RIGHT_MIDDY_MOD == LSFT || RIGHT_MIDDY_MOD == RSFT
        hold-while-undecided; // requires 24.08-beta1 or newer firmware
        retro-tap; // tap on standalone hold
      #endif
    #endif
  };
  right_middy_hold: homey_right_middy_hold {
    compatible = "zmk,behavior-macro-one-param";
    wait-ms = <0>;
    tap-ms = <0>;
    #binding-cells = <1>;
    bindings
      = <&macro_param_1to1>
      , <&macro_press &kp MACRO_PLACEHOLDER>
      #ifdef LAYER_RightMiddy
      , <&macro_press &mo LAYER_RightMiddy>
      #endif
      , <&macro_pause_for_release>
      , <&macro_param_1to1>
      , <&macro_release &kp MACRO_PLACEHOLDER>
      #ifdef LAYER_RightMiddy
      , <&macro_release &mo LAYER_RightMiddy>
      #endif
      ;
  };
  right_middy_tap: homey_right_middy_tap {
    compatible = "zmk,behavior-macro-one-param";
    wait-ms = <0>;
    tap-ms = <0>;
    #binding-cells = <1>;
    bindings
      = <&macro_release
          &kp LSFT &kp RSFT
          &kp LALT &kp RALT
          &kp LCTL &kp RCTL
          &kp LGUI &kp RGUI>
      , <&macro_tap &kp RIGHT_MIDDY_KEY>
      , <&macro_param_1to1>
      , <&macro_tap &kp MACRO_PLACEHOLDER>
      ;
  };
  #define RightMiddy(key, layer_index) RightMiddy_unroll(layer_index) (key)
  #define RightMiddy_unroll(layer_index) RightMiddy_concat(RightMiddy_layer, layer_index)
  #define RightMiddy_concat(prefix, layer_index) prefix ## layer_index
  #ifdef ENFORCE_BILATERAL
    #define right_middy_layer0_variant right_middy_bilateral
  #else
    #define right_middy_layer0_variant right_middy
  #endif
  #define RightMiddy_layer0(key) right_middy_layer0_variant RIGHT_MIDDY_MOD key
  #ifndef LEFT_INDEX_HOLDING_TYPE
  #define LEFT_INDEX_HOLDING_TYPE INDEX_HOLDING_TYPE
  #endif
  #ifndef LEFT_INDEX_HOLDING_TIME
  #define LEFT_INDEX_HOLDING_TIME INDEX_HOLDING_TIME
  #endif
  #ifndef LEFT_INDEX_STREAK_DECAY
  #define LEFT_INDEX_STREAK_DECAY INDEX_STREAK_DECAY
  #endif
  #ifndef LEFT_INDEX_REPEAT_DECAY
  #define LEFT_INDEX_REPEAT_DECAY INDEX_REPEAT_DECAY
  #endif
  left_index: homey_left_index {
    compatible = "zmk,behavior-hold-tap";
    flavor = LEFT_INDEX_HOLDING_TYPE;
    hold-trigger-key-positions = <RIGHT_HAND_KEYS>;
    hold-trigger-on-release; // wait for other home row mods
    tapping-term-ms = <LEFT_INDEX_HOLDING_TIME>;
    quick-tap-ms = <LEFT_INDEX_REPEAT_DECAY>;
    require-prior-idle-ms = <LEFT_INDEX_STREAK_DECAY>;
    #binding-cells = <2>;
    bindings = <&kp>, <&kp>;
    #ifdef SHIFT_FORGIVENESS
      #if LEFT_INDEX_MOD == LSFT || LEFT_INDEX_MOD == RSFT
        hold-while-undecided; // requires 24.08-beta1 or newer firmware
        retro-tap; // tap on standalone hold
      #endif
    #endif
  };
  left_index_bilateral: homey_left_index_bilateral {
    compatible = "zmk,behavior-hold-tap";
    flavor = LEFT_INDEX_HOLDING_TYPE;
    hold-trigger-key-positions = <RIGHT_HAND_KEYS>;
    hold-trigger-on-release; // wait for other home row mods
    tapping-term-ms = <LEFT_INDEX_HOLDING_TIME>;
    quick-tap-ms = <LEFT_INDEX_REPEAT_DECAY>;
    require-prior-idle-ms = <LEFT_INDEX_STREAK_DECAY>;
    #binding-cells = <2>;
    bindings = <&left_index_hold>, <&kp>;
    #ifdef SHIFT_FORGIVENESS
      #if LEFT_INDEX_MOD == LSFT || LEFT_INDEX_MOD == RSFT
        hold-while-undecided; // requires 24.08-beta1 or newer firmware
        retro-tap; // tap on standalone hold
      #endif
    #endif
  };
  left_index_hold: homey_left_index_hold {
    compatible = "zmk,behavior-macro-one-param";
    wait-ms = <0>;
    tap-ms = <0>;
    #binding-cells = <1>;
    bindings
      = <&macro_param_1to1>
      , <&macro_press &kp MACRO_PLACEHOLDER>
      #ifdef LAYER_LeftIndex
      , <&macro_press &mo LAYER_LeftIndex>
      #endif
      , <&macro_pause_for_release>
      , <&macro_param_1to1>
      , <&macro_release &kp MACRO_PLACEHOLDER>
      #ifdef LAYER_LeftIndex
      , <&macro_release &mo LAYER_LeftIndex>
      #endif
      ;
  };
  left_index_tap: homey_left_index_tap {
    compatible = "zmk,behavior-macro-one-param";
    wait-ms = <0>;
    tap-ms = <0>;
    #binding-cells = <1>;
    bindings
      = <&macro_release
          &kp LSFT &kp RSFT
          &kp LALT &kp RALT
          &kp LCTL &kp RCTL
          &kp LGUI &kp RGUI>
      , <&macro_tap &kp LEFT_INDEX_KEY>
      , <&macro_param_1to1>
      , <&macro_tap &kp MACRO_PLACEHOLDER>
      ;
  };
  #define LeftIndex(key, layer_index) LeftIndex_unroll(layer_index) (key)
  #define LeftIndex_unroll(layer_index) LeftIndex_concat(LeftIndex_layer, layer_index)
  #define LeftIndex_concat(prefix, layer_index) prefix ## layer_index
  #ifdef ENFORCE_BILATERAL
    #define left_index_layer0_variant left_index_bilateral
  #else
    #define left_index_layer0_variant left_index
  #endif
  #define LeftIndex_layer0(key) left_index_layer0_variant LEFT_INDEX_MOD key
  #ifndef RIGHT_INDEX_HOLDING_TYPE
  #define RIGHT_INDEX_HOLDING_TYPE INDEX_HOLDING_TYPE
  #endif
  #ifndef RIGHT_INDEX_HOLDING_TIME
  #define RIGHT_INDEX_HOLDING_TIME INDEX_HOLDING_TIME
  #endif
  #ifndef RIGHT_INDEX_STREAK_DECAY
  #define RIGHT_INDEX_STREAK_DECAY INDEX_STREAK_DECAY
  #endif
  #ifndef RIGHT_INDEX_REPEAT_DECAY
  #define RIGHT_INDEX_REPEAT_DECAY INDEX_REPEAT_DECAY
  #endif
  right_index: homey_right_index {
    compatible = "zmk,behavior-hold-tap";
    flavor = RIGHT_INDEX_HOLDING_TYPE;
    hold-trigger-key-positions = <LEFT_HAND_KEYS>;
    hold-trigger-on-release; // wait for other home row mods
    tapping-term-ms = <RIGHT_INDEX_HOLDING_TIME>;
    quick-tap-ms = <RIGHT_INDEX_REPEAT_DECAY>;
    require-prior-idle-ms = <RIGHT_INDEX_STREAK_DECAY>;
    #binding-cells = <2>;
    bindings = <&kp>, <&kp>;
    #ifdef SHIFT_FORGIVENESS
      #if RIGHT_INDEX_MOD == LSFT || RIGHT_INDEX_MOD == RSFT
        hold-while-undecided; // requires 24.08-beta1 or newer firmware
        retro-tap; // tap on standalone hold
      #endif
    #endif
  };
  right_index_bilateral: homey_right_index_bilateral {
    compatible = "zmk,behavior-hold-tap";
    flavor = RIGHT_INDEX_HOLDING_TYPE;
    hold-trigger-key-positions = <LEFT_HAND_KEYS>;
    hold-trigger-on-release; // wait for other home row mods
    tapping-term-ms = <RIGHT_INDEX_HOLDING_TIME>;
    quick-tap-ms = <RIGHT_INDEX_REPEAT_DECAY>;
    require-prior-idle-ms = <RIGHT_INDEX_STREAK_DECAY>;
    #binding-cells = <2>;
    bindings = <&right_index_hold>, <&kp>;
    #ifdef SHIFT_FORGIVENESS
      #if RIGHT_INDEX_MOD == LSFT || RIGHT_INDEX_MOD == RSFT
        hold-while-undecided; // requires 24.08-beta1 or newer firmware
        retro-tap; // tap on standalone hold
      #endif
    #endif
  };
  right_index_hold: homey_right_index_hold {
    compatible = "zmk,behavior-macro-one-param";
    wait-ms = <0>;
    tap-ms = <0>;
    #binding-cells = <1>;
    bindings
      = <&macro_param_1to1>
      , <&macro_press &kp MACRO_PLACEHOLDER>
      #ifdef LAYER_RightIndex
      , <&macro_press &mo LAYER_RightIndex>
      #endif
      , <&macro_pause_for_release>
      , <&macro_param_1to1>
      , <&macro_release &kp MACRO_PLACEHOLDER>
      #ifdef LAYER_RightIndex
      , <&macro_release &mo LAYER_RightIndex>
      #endif
      ;
  };
  right_index_tap: homey_right_index_tap {
    compatible = "zmk,behavior-macro-one-param";
    wait-ms = <0>;
    tap-ms = <0>;
    #binding-cells = <1>;
    bindings
      = <&macro_release
          &kp LSFT &kp RSFT
          &kp LALT &kp RALT
          &kp LCTL &kp RCTL
          &kp LGUI &kp RGUI>
      , <&macro_tap &kp RIGHT_INDEX_KEY>
      , <&macro_param_1to1>
      , <&macro_tap &kp MACRO_PLACEHOLDER>
      ;
  };
  #define RightIndex(key, layer_index) RightIndex_unroll(layer_index) (key)
  #define RightIndex_unroll(layer_index) RightIndex_concat(RightIndex_layer, layer_index)
  #define RightIndex_concat(prefix, layer_index) prefix ## layer_index
  #ifdef ENFORCE_BILATERAL
    #define right_index_layer0_variant right_index_bilateral
  #else
    #define right_index_layer0_variant right_index
  #endif
  #define RightIndex_layer0(key) right_index_layer0_variant RIGHT_INDEX_MOD key
  #ifndef LEFT_RINGY_PINKY_HOLDING_TYPE
  #define LEFT_RINGY_PINKY_HOLDING_TYPE LEFT_RINGY_CHORD_HOLDING_TYPE
  #endif
  #ifndef LEFT_RINGY_PINKY_HOLDING_TIME
  #define LEFT_RINGY_PINKY_HOLDING_TIME LEFT_RINGY_CHORD_HOLDING_TIME
  #endif
  #ifndef LEFT_RINGY_PINKY_STREAK_DECAY
  #define LEFT_RINGY_PINKY_STREAK_DECAY LEFT_RINGY_CHORD_STREAK_DECAY
  #endif
  #ifndef LEFT_RINGY_PINKY_REPEAT_DECAY
  #define LEFT_RINGY_PINKY_REPEAT_DECAY LEFT_RINGY_CHORD_REPEAT_DECAY
  #endif
  left_ringy_pinky: homey_left_ringy_pinky {
    compatible = "zmk,behavior-hold-tap";
    flavor = LEFT_RINGY_HOLDING_TYPE;
    hold-trigger-key-positions = <RIGHT_HAND_KEYS>;
    hold-trigger-on-release; // wait for other home row mods
    tapping-term-ms = <LEFT_RINGY_HOLDING_TIME>;
    quick-tap-ms = <LEFT_RINGY_REPEAT_DECAY>;
    require-prior-idle-ms = <LEFT_RINGY_STREAK_DECAY>;
    #binding-cells = <2>;
    bindings = <&kp>, <&kp>;
  };
  left_ringy_pinky_bilateral: homey_left_ringy_pinky_bilateral {
    compatible = "zmk,behavior-hold-tap";
    flavor = LEFT_RINGY_HOLDING_TYPE;
    hold-trigger-key-positions = <RIGHT_HAND_KEYS>;
    hold-trigger-on-release; // wait for other home row mods
    tapping-term-ms = <LEFT_RINGY_HOLDING_TIME>;
    quick-tap-ms = <LEFT_RINGY_REPEAT_DECAY>;
    require-prior-idle-ms = <LEFT_RINGY_STREAK_DECAY>;
    #binding-cells = <2>;
    bindings = <&kp>, <&left_ringy_tap>;
  };
  #define LeftRingyPinky left_ringy_pinky_bilateral LEFT_PINKY_MOD LEFT_PINKY_KEY
  #ifndef LEFT_MIDDY_PINKY_HOLDING_TYPE
  #define LEFT_MIDDY_PINKY_HOLDING_TYPE LEFT_MIDDY_CHORD_HOLDING_TYPE
  #endif
  #ifndef LEFT_MIDDY_PINKY_HOLDING_TIME
  #define LEFT_MIDDY_PINKY_HOLDING_TIME LEFT_MIDDY_CHORD_HOLDING_TIME
  #endif
  #ifndef LEFT_MIDDY_PINKY_STREAK_DECAY
  #define LEFT_MIDDY_PINKY_STREAK_DECAY LEFT_MIDDY_CHORD_STREAK_DECAY
  #endif
  #ifndef LEFT_MIDDY_PINKY_REPEAT_DECAY
  #define LEFT_MIDDY_PINKY_REPEAT_DECAY LEFT_MIDDY_CHORD_REPEAT_DECAY
  #endif
  left_middy_pinky: homey_left_middy_pinky {
    compatible = "zmk,behavior-hold-tap";
    flavor = LEFT_MIDDY_HOLDING_TYPE;
    hold-trigger-key-positions = <RIGHT_HAND_KEYS>;
    hold-trigger-on-release; // wait for other home row mods
    tapping-term-ms = <LEFT_MIDDY_HOLDING_TIME>;
    quick-tap-ms = <LEFT_MIDDY_REPEAT_DECAY>;
    require-prior-idle-ms = <LEFT_MIDDY_STREAK_DECAY>;
    #binding-cells = <2>;
    bindings = <&kp>, <&kp>;
  };
  left_middy_pinky_bilateral: homey_left_middy_pinky_bilateral {
    compatible = "zmk,behavior-hold-tap";
    flavor = LEFT_MIDDY_HOLDING_TYPE;
    hold-trigger-key-positions = <RIGHT_HAND_KEYS>;
    hold-trigger-on-release; // wait for other home row mods
    tapping-term-ms = <LEFT_MIDDY_HOLDING_TIME>;
    quick-tap-ms = <LEFT_MIDDY_REPEAT_DECAY>;
    require-prior-idle-ms = <LEFT_MIDDY_STREAK_DECAY>;
    #binding-cells = <2>;
    bindings = <&kp>, <&left_middy_tap>;
  };
  #define LeftMiddyPinky left_middy_pinky_bilateral LEFT_PINKY_MOD LEFT_PINKY_KEY
  #ifndef LEFT_INDEX_PINKY_HOLDING_TYPE
  #define LEFT_INDEX_PINKY_HOLDING_TYPE LEFT_INDEX_CHORD_HOLDING_TYPE
  #endif
  #ifndef LEFT_INDEX_PINKY_HOLDING_TIME
  #define LEFT_INDEX_PINKY_HOLDING_TIME LEFT_INDEX_CHORD_HOLDING_TIME
  #endif
  #ifndef LEFT_INDEX_PINKY_STREAK_DECAY
  #define LEFT_INDEX_PINKY_STREAK_DECAY LEFT_INDEX_CHORD_STREAK_DECAY
  #endif
  #ifndef LEFT_INDEX_PINKY_REPEAT_DECAY
  #define LEFT_INDEX_PINKY_REPEAT_DECAY LEFT_INDEX_CHORD_REPEAT_DECAY
  #endif
  left_index_pinky: homey_left_index_pinky {
    compatible = "zmk,behavior-hold-tap";
    flavor = LEFT_INDEX_HOLDING_TYPE;
    hold-trigger-key-positions = <RIGHT_HAND_KEYS>;
    hold-trigger-on-release; // wait for other home row mods
    tapping-term-ms = <LEFT_INDEX_HOLDING_TIME>;
    quick-tap-ms = <LEFT_INDEX_REPEAT_DECAY>;
    require-prior-idle-ms = <LEFT_INDEX_STREAK_DECAY>;
    #binding-cells = <2>;
    bindings = <&kp>, <&kp>;
  };
  left_index_pinky_bilateral: homey_left_index_pinky_bilateral {
    compatible = "zmk,behavior-hold-tap";
    flavor = LEFT_INDEX_HOLDING_TYPE;
    hold-trigger-key-positions = <RIGHT_HAND_KEYS>;
    hold-trigger-on-release; // wait for other home row mods
    tapping-term-ms = <LEFT_INDEX_HOLDING_TIME>;
    quick-tap-ms = <LEFT_INDEX_REPEAT_DECAY>;
    require-prior-idle-ms = <LEFT_INDEX_STREAK_DECAY>;
    #binding-cells = <2>;
    bindings = <&kp>, <&left_index_tap>;
  };
  #define LeftIndexPinky left_index_pinky_bilateral LEFT_PINKY_MOD LEFT_PINKY_KEY
  #ifndef RIGHT_RINGY_PINKY_HOLDING_TYPE
  #define RIGHT_RINGY_PINKY_HOLDING_TYPE RIGHT_RINGY_CHORD_HOLDING_TYPE
  #endif
  #ifndef RIGHT_RINGY_PINKY_HOLDING_TIME
  #define RIGHT_RINGY_PINKY_HOLDING_TIME RIGHT_RINGY_CHORD_HOLDING_TIME
  #endif
  #ifndef RIGHT_RINGY_PINKY_STREAK_DECAY
  #define RIGHT_RINGY_PINKY_STREAK_DECAY RIGHT_RINGY_CHORD_STREAK_DECAY
  #endif
  #ifndef RIGHT_RINGY_PINKY_REPEAT_DECAY
  #define RIGHT_RINGY_PINKY_REPEAT_DECAY RIGHT_RINGY_CHORD_REPEAT_DECAY
  #endif
  right_ringy_pinky: homey_right_ringy_pinky {
    compatible = "zmk,behavior-hold-tap";
    flavor = RIGHT_RINGY_HOLDING_TYPE;
    hold-trigger-key-positions = <LEFT_HAND_KEYS>;
    hold-trigger-on-release; // wait for other home row mods
    tapping-term-ms = <RIGHT_RINGY_HOLDING_TIME>;
    quick-tap-ms = <RIGHT_RINGY_REPEAT_DECAY>;
    require-prior-idle-ms = <RIGHT_RINGY_STREAK_DECAY>;
    #binding-cells = <2>;
    bindings = <&kp>, <&kp>;
  };
  right_ringy_pinky_bilateral: homey_right_ringy_pinky_bilateral {
    compatible = "zmk,behavior-hold-tap";
    flavor = RIGHT_RINGY_HOLDING_TYPE;
    hold-trigger-key-positions = <LEFT_HAND_KEYS>;
    hold-trigger-on-release; // wait for other home row mods
    tapping-term-ms = <RIGHT_RINGY_HOLDING_TIME>;
    quick-tap-ms = <RIGHT_RINGY_REPEAT_DECAY>;
    require-prior-idle-ms = <RIGHT_RINGY_STREAK_DECAY>;
    #binding-cells = <2>;
    bindings = <&kp>, <&right_ringy_tap>;
  };
  #define RightRingyPinky right_ringy_pinky_bilateral RIGHT_PINKY_MOD RIGHT_PINKY_KEY
  #ifndef RIGHT_MIDDY_PINKY_HOLDING_TYPE
  #define RIGHT_MIDDY_PINKY_HOLDING_TYPE RIGHT_MIDDY_CHORD_HOLDING_TYPE
  #endif
  #ifndef RIGHT_MIDDY_PINKY_HOLDING_TIME
  #define RIGHT_MIDDY_PINKY_HOLDING_TIME RIGHT_MIDDY_CHORD_HOLDING_TIME
  #endif
  #ifndef RIGHT_MIDDY_PINKY_STREAK_DECAY
  #define RIGHT_MIDDY_PINKY_STREAK_DECAY RIGHT_MIDDY_CHORD_STREAK_DECAY
  #endif
  #ifndef RIGHT_MIDDY_PINKY_REPEAT_DECAY
  #define RIGHT_MIDDY_PINKY_REPEAT_DECAY RIGHT_MIDDY_CHORD_REPEAT_DECAY
  #endif
  right_middy_pinky: homey_right_middy_pinky {
    compatible = "zmk,behavior-hold-tap";
    flavor = RIGHT_MIDDY_HOLDING_TYPE;
    hold-trigger-key-positions = <LEFT_HAND_KEYS>;
    hold-trigger-on-release; // wait for other home row mods
    tapping-term-ms = <RIGHT_MIDDY_HOLDING_TIME>;
    quick-tap-ms = <RIGHT_MIDDY_REPEAT_DECAY>;
    require-prior-idle-ms = <RIGHT_MIDDY_STREAK_DECAY>;
    #binding-cells = <2>;
    bindings = <&kp>, <&kp>;
  };
  right_middy_pinky_bilateral: homey_right_middy_pinky_bilateral {
    compatible = "zmk,behavior-hold-tap";
    flavor = RIGHT_MIDDY_HOLDING_TYPE;
    hold-trigger-key-positions = <LEFT_HAND_KEYS>;
    hold-trigger-on-release; // wait for other home row mods
    tapping-term-ms = <RIGHT_MIDDY_HOLDING_TIME>;
    quick-tap-ms = <RIGHT_MIDDY_REPEAT_DECAY>;
    require-prior-idle-ms = <RIGHT_MIDDY_STREAK_DECAY>;
    #binding-cells = <2>;
    bindings = <&kp>, <&right_middy_tap>;
  };
  #define RightMiddyPinky right_middy_pinky_bilateral RIGHT_PINKY_MOD RIGHT_PINKY_KEY
  #ifndef RIGHT_INDEX_PINKY_HOLDING_TYPE
  #define RIGHT_INDEX_PINKY_HOLDING_TYPE RIGHT_INDEX_CHORD_HOLDING_TYPE
  #endif
  #ifndef RIGHT_INDEX_PINKY_HOLDING_TIME
  #define RIGHT_INDEX_PINKY_HOLDING_TIME RIGHT_INDEX_CHORD_HOLDING_TIME
  #endif
  #ifndef RIGHT_INDEX_PINKY_STREAK_DECAY
  #define RIGHT_INDEX_PINKY_STREAK_DECAY RIGHT_INDEX_CHORD_STREAK_DECAY
  #endif
  #ifndef RIGHT_INDEX_PINKY_REPEAT_DECAY
  #define RIGHT_INDEX_PINKY_REPEAT_DECAY RIGHT_INDEX_CHORD_REPEAT_DECAY
  #endif
  right_index_pinky: homey_right_index_pinky {
    compatible = "zmk,behavior-hold-tap";
    flavor = RIGHT_INDEX_HOLDING_TYPE;
    hold-trigger-key-positions = <LEFT_HAND_KEYS>;
    hold-trigger-on-release; // wait for other home row mods
    tapping-term-ms = <RIGHT_INDEX_HOLDING_TIME>;
    quick-tap-ms = <RIGHT_INDEX_REPEAT_DECAY>;
    require-prior-idle-ms = <RIGHT_INDEX_STREAK_DECAY>;
    #binding-cells = <2>;
    bindings = <&kp>, <&kp>;
  };
  right_index_pinky_bilateral: homey_right_index_pinky_bilateral {
    compatible = "zmk,behavior-hold-tap";
    flavor = RIGHT_INDEX_HOLDING_TYPE;
    hold-trigger-key-positions = <LEFT_HAND_KEYS>;
    hold-trigger-on-release; // wait for other home row mods
    tapping-term-ms = <RIGHT_INDEX_HOLDING_TIME>;
    quick-tap-ms = <RIGHT_INDEX_REPEAT_DECAY>;
    require-prior-idle-ms = <RIGHT_INDEX_STREAK_DECAY>;
    #binding-cells = <2>;
    bindings = <&kp>, <&right_index_tap>;
  };
  #define RightIndexPinky right_index_pinky_bilateral RIGHT_PINKY_MOD RIGHT_PINKY_KEY
  #ifndef LEFT_PINKY_RINGY_HOLDING_TYPE
  #define LEFT_PINKY_RINGY_HOLDING_TYPE LEFT_PINKY_CHORD_HOLDING_TYPE
  #endif
  #ifndef LEFT_PINKY_RINGY_HOLDING_TIME
  #define LEFT_PINKY_RINGY_HOLDING_TIME LEFT_PINKY_CHORD_HOLDING_TIME
  #endif
  #ifndef LEFT_PINKY_RINGY_STREAK_DECAY
  #define LEFT_PINKY_RINGY_STREAK_DECAY LEFT_PINKY_CHORD_STREAK_DECAY
  #endif
  #ifndef LEFT_PINKY_RINGY_REPEAT_DECAY
  #define LEFT_PINKY_RINGY_REPEAT_DECAY LEFT_PINKY_CHORD_REPEAT_DECAY
  #endif
  left_pinky_ringy: homey_left_pinky_ringy {
    compatible = "zmk,behavior-hold-tap";
    flavor = LEFT_PINKY_HOLDING_TYPE;
    hold-trigger-key-positions = <RIGHT_HAND_KEYS>;
    hold-trigger-on-release; // wait for other home row mods
    tapping-term-ms = <LEFT_PINKY_HOLDING_TIME>;
    quick-tap-ms = <LEFT_PINKY_REPEAT_DECAY>;
    require-prior-idle-ms = <LEFT_PINKY_STREAK_DECAY>;
    #binding-cells = <2>;
    bindings = <&kp>, <&kp>;
  };
  left_pinky_ringy_bilateral: homey_left_pinky_ringy_bilateral {
    compatible = "zmk,behavior-hold-tap";
    flavor = LEFT_PINKY_HOLDING_TYPE;
    hold-trigger-key-positions = <RIGHT_HAND_KEYS>;
    hold-trigger-on-release; // wait for other home row mods
    tapping-term-ms = <LEFT_PINKY_HOLDING_TIME>;
    quick-tap-ms = <LEFT_PINKY_REPEAT_DECAY>;
    require-prior-idle-ms = <LEFT_PINKY_STREAK_DECAY>;
    #binding-cells = <2>;
    bindings = <&kp>, <&left_pinky_tap>;
  };
  #define LeftPinkyRingy left_pinky_ringy_bilateral LEFT_RINGY_MOD LEFT_RINGY_KEY
  #ifndef LEFT_MIDDY_RINGY_HOLDING_TYPE
  #define LEFT_MIDDY_RINGY_HOLDING_TYPE LEFT_MIDDY_CHORD_HOLDING_TYPE
  #endif
  #ifndef LEFT_MIDDY_RINGY_HOLDING_TIME
  #define LEFT_MIDDY_RINGY_HOLDING_TIME LEFT_MIDDY_CHORD_HOLDING_TIME
  #endif
  #ifndef LEFT_MIDDY_RINGY_STREAK_DECAY
  #define LEFT_MIDDY_RINGY_STREAK_DECAY LEFT_MIDDY_CHORD_STREAK_DECAY
  #endif
  #ifndef LEFT_MIDDY_RINGY_REPEAT_DECAY
  #define LEFT_MIDDY_RINGY_REPEAT_DECAY LEFT_MIDDY_CHORD_REPEAT_DECAY
  #endif
  left_middy_ringy: homey_left_middy_ringy {
    compatible = "zmk,behavior-hold-tap";
    flavor = LEFT_MIDDY_HOLDING_TYPE;
    hold-trigger-key-positions = <RIGHT_HAND_KEYS>;
    hold-trigger-on-release; // wait for other home row mods
    tapping-term-ms = <LEFT_MIDDY_HOLDING_TIME>;
    quick-tap-ms = <LEFT_MIDDY_REPEAT_DECAY>;
    require-prior-idle-ms = <LEFT_MIDDY_STREAK_DECAY>;
    #binding-cells = <2>;
    bindings = <&kp>, <&kp>;
  };
  left_middy_ringy_bilateral: homey_left_middy_ringy_bilateral {
    compatible = "zmk,behavior-hold-tap";
    flavor = LEFT_MIDDY_HOLDING_TYPE;
    hold-trigger-key-positions = <RIGHT_HAND_KEYS>;
    hold-trigger-on-release; // wait for other home row mods
    tapping-term-ms = <LEFT_MIDDY_HOLDING_TIME>;
    quick-tap-ms = <LEFT_MIDDY_REPEAT_DECAY>;
    require-prior-idle-ms = <LEFT_MIDDY_STREAK_DECAY>;
    #binding-cells = <2>;
    bindings = <&kp>, <&left_middy_tap>;
  };
  #define LeftMiddyRingy left_middy_ringy_bilateral LEFT_RINGY_MOD LEFT_RINGY_KEY
  #ifndef LEFT_INDEX_RINGY_HOLDING_TYPE
  #define LEFT_INDEX_RINGY_HOLDING_TYPE LEFT_INDEX_CHORD_HOLDING_TYPE
  #endif
  #ifndef LEFT_INDEX_RINGY_HOLDING_TIME
  #define LEFT_INDEX_RINGY_HOLDING_TIME LEFT_INDEX_CHORD_HOLDING_TIME
  #endif
  #ifndef LEFT_INDEX_RINGY_STREAK_DECAY
  #define LEFT_INDEX_RINGY_STREAK_DECAY LEFT_INDEX_CHORD_STREAK_DECAY
  #endif
  #ifndef LEFT_INDEX_RINGY_REPEAT_DECAY
  #define LEFT_INDEX_RINGY_REPEAT_DECAY LEFT_INDEX_CHORD_REPEAT_DECAY
  #endif
  left_index_ringy: homey_left_index_ringy {
    compatible = "zmk,behavior-hold-tap";
    flavor = LEFT_INDEX_HOLDING_TYPE;
    hold-trigger-key-positions = <RIGHT_HAND_KEYS>;
    hold-trigger-on-release; // wait for other home row mods
    tapping-term-ms = <LEFT_INDEX_HOLDING_TIME>;
    quick-tap-ms = <LEFT_INDEX_REPEAT_DECAY>;
    require-prior-idle-ms = <LEFT_INDEX_STREAK_DECAY>;
    #binding-cells = <2>;
    bindings = <&kp>, <&kp>;
  };
  left_index_ringy_bilateral: homey_left_index_ringy_bilateral {
    compatible = "zmk,behavior-hold-tap";
    flavor = LEFT_INDEX_HOLDING_TYPE;
    hold-trigger-key-positions = <RIGHT_HAND_KEYS>;
    hold-trigger-on-release; // wait for other home row mods
    tapping-term-ms = <LEFT_INDEX_HOLDING_TIME>;
    quick-tap-ms = <LEFT_INDEX_REPEAT_DECAY>;
    require-prior-idle-ms = <LEFT_INDEX_STREAK_DECAY>;
    #binding-cells = <2>;
    bindings = <&kp>, <&left_index_tap>;
  };
  #define LeftIndexRingy left_index_ringy_bilateral LEFT_RINGY_MOD LEFT_RINGY_KEY
  #ifndef RIGHT_PINKY_RINGY_HOLDING_TYPE
  #define RIGHT_PINKY_RINGY_HOLDING_TYPE RIGHT_PINKY_CHORD_HOLDING_TYPE
  #endif
  #ifndef RIGHT_PINKY_RINGY_HOLDING_TIME
  #define RIGHT_PINKY_RINGY_HOLDING_TIME RIGHT_PINKY_CHORD_HOLDING_TIME
  #endif
  #ifndef RIGHT_PINKY_RINGY_STREAK_DECAY
  #define RIGHT_PINKY_RINGY_STREAK_DECAY RIGHT_PINKY_CHORD_STREAK_DECAY
  #endif
  #ifndef RIGHT_PINKY_RINGY_REPEAT_DECAY
  #define RIGHT_PINKY_RINGY_REPEAT_DECAY RIGHT_PINKY_CHORD_REPEAT_DECAY
  #endif
  right_pinky_ringy: homey_right_pinky_ringy {
    compatible = "zmk,behavior-hold-tap";
    flavor = RIGHT_PINKY_HOLDING_TYPE;
    hold-trigger-key-positions = <LEFT_HAND_KEYS>;
    hold-trigger-on-release; // wait for other home row mods
    tapping-term-ms = <RIGHT_PINKY_HOLDING_TIME>;
    quick-tap-ms = <RIGHT_PINKY_REPEAT_DECAY>;
    require-prior-idle-ms = <RIGHT_PINKY_STREAK_DECAY>;
    #binding-cells = <2>;
    bindings = <&kp>, <&kp>;
  };
  right_pinky_ringy_bilateral: homey_right_pinky_ringy_bilateral {
    compatible = "zmk,behavior-hold-tap";
    flavor = RIGHT_PINKY_HOLDING_TYPE;
    hold-trigger-key-positions = <LEFT_HAND_KEYS>;
    hold-trigger-on-release; // wait for other home row mods
    tapping-term-ms = <RIGHT_PINKY_HOLDING_TIME>;
    quick-tap-ms = <RIGHT_PINKY_REPEAT_DECAY>;
    require-prior-idle-ms = <RIGHT_PINKY_STREAK_DECAY>;
    #binding-cells = <2>;
    bindings = <&kp>, <&right_pinky_tap>;
  };
  #define RightPinkyRingy right_pinky_ringy_bilateral RIGHT_RINGY_MOD RIGHT_RINGY_KEY
  #ifndef RIGHT_MIDDY_RINGY_HOLDING_TYPE
  #define RIGHT_MIDDY_RINGY_HOLDING_TYPE RIGHT_MIDDY_CHORD_HOLDING_TYPE
  #endif
  #ifndef RIGHT_MIDDY_RINGY_HOLDING_TIME
  #define RIGHT_MIDDY_RINGY_HOLDING_TIME RIGHT_MIDDY_CHORD_HOLDING_TIME
  #endif
  #ifndef RIGHT_MIDDY_RINGY_STREAK_DECAY
  #define RIGHT_MIDDY_RINGY_STREAK_DECAY RIGHT_MIDDY_CHORD_STREAK_DECAY
  #endif
  #ifndef RIGHT_MIDDY_RINGY_REPEAT_DECAY
  #define RIGHT_MIDDY_RINGY_REPEAT_DECAY RIGHT_MIDDY_CHORD_REPEAT_DECAY
  #endif
  right_middy_ringy: homey_right_middy_ringy {
    compatible = "zmk,behavior-hold-tap";
    flavor = RIGHT_MIDDY_HOLDING_TYPE;
    hold-trigger-key-positions = <LEFT_HAND_KEYS>;
    hold-trigger-on-release; // wait for other home row mods
    tapping-term-ms = <RIGHT_MIDDY_HOLDING_TIME>;
    quick-tap-ms = <RIGHT_MIDDY_REPEAT_DECAY>;
    require-prior-idle-ms = <RIGHT_MIDDY_STREAK_DECAY>;
    #binding-cells = <2>;
    bindings = <&kp>, <&kp>;
  };
  right_middy_ringy_bilateral: homey_right_middy_ringy_bilateral {
    compatible = "zmk,behavior-hold-tap";
    flavor = RIGHT_MIDDY_HOLDING_TYPE;
    hold-trigger-key-positions = <LEFT_HAND_KEYS>;
    hold-trigger-on-release; // wait for other home row mods
    tapping-term-ms = <RIGHT_MIDDY_HOLDING_TIME>;
    quick-tap-ms = <RIGHT_MIDDY_REPEAT_DECAY>;
    require-prior-idle-ms = <RIGHT_MIDDY_STREAK_DECAY>;
    #binding-cells = <2>;
    bindings = <&kp>, <&right_middy_tap>;
  };
  #define RightMiddyRingy right_middy_ringy_bilateral RIGHT_RINGY_MOD RIGHT_RINGY_KEY
  #ifndef RIGHT_INDEX_RINGY_HOLDING_TYPE
  #define RIGHT_INDEX_RINGY_HOLDING_TYPE RIGHT_INDEX_CHORD_HOLDING_TYPE
  #endif
  #ifndef RIGHT_INDEX_RINGY_HOLDING_TIME
  #define RIGHT_INDEX_RINGY_HOLDING_TIME RIGHT_INDEX_CHORD_HOLDING_TIME
  #endif
  #ifndef RIGHT_INDEX_RINGY_STREAK_DECAY
  #define RIGHT_INDEX_RINGY_STREAK_DECAY RIGHT_INDEX_CHORD_STREAK_DECAY
  #endif
  #ifndef RIGHT_INDEX_RINGY_REPEAT_DECAY
  #define RIGHT_INDEX_RINGY_REPEAT_DECAY RIGHT_INDEX_CHORD_REPEAT_DECAY
  #endif
  right_index_ringy: homey_right_index_ringy {
    compatible = "zmk,behavior-hold-tap";
    flavor = RIGHT_INDEX_HOLDING_TYPE;
    hold-trigger-key-positions = <LEFT_HAND_KEYS>;
    hold-trigger-on-release; // wait for other home row mods
    tapping-term-ms = <RIGHT_INDEX_HOLDING_TIME>;
    quick-tap-ms = <RIGHT_INDEX_REPEAT_DECAY>;
    require-prior-idle-ms = <RIGHT_INDEX_STREAK_DECAY>;
    #binding-cells = <2>;
    bindings = <&kp>, <&kp>;
  };
  right_index_ringy_bilateral: homey_right_index_ringy_bilateral {
    compatible = "zmk,behavior-hold-tap";
    flavor = RIGHT_INDEX_HOLDING_TYPE;
    hold-trigger-key-positions = <LEFT_HAND_KEYS>;
    hold-trigger-on-release; // wait for other home row mods
    tapping-term-ms = <RIGHT_INDEX_HOLDING_TIME>;
    quick-tap-ms = <RIGHT_INDEX_REPEAT_DECAY>;
    require-prior-idle-ms = <RIGHT_INDEX_STREAK_DECAY>;
    #binding-cells = <2>;
    bindings = <&kp>, <&right_index_tap>;
  };
  #define RightIndexRingy right_index_ringy_bilateral RIGHT_RINGY_MOD RIGHT_RINGY_KEY
  #ifndef LEFT_PINKY_MIDDY_HOLDING_TYPE
  #define LEFT_PINKY_MIDDY_HOLDING_TYPE LEFT_PINKY_CHORD_HOLDING_TYPE
  #endif
  #ifndef LEFT_PINKY_MIDDY_HOLDING_TIME
  #define LEFT_PINKY_MIDDY_HOLDING_TIME LEFT_PINKY_CHORD_HOLDING_TIME
  #endif
  #ifndef LEFT_PINKY_MIDDY_STREAK_DECAY
  #define LEFT_PINKY_MIDDY_STREAK_DECAY LEFT_PINKY_CHORD_STREAK_DECAY
  #endif
  #ifndef LEFT_PINKY_MIDDY_REPEAT_DECAY
  #define LEFT_PINKY_MIDDY_REPEAT_DECAY LEFT_PINKY_CHORD_REPEAT_DECAY
  #endif
  left_pinky_middy: homey_left_pinky_middy {
    compatible = "zmk,behavior-hold-tap";
    flavor = LEFT_PINKY_HOLDING_TYPE;
    hold-trigger-key-positions = <RIGHT_HAND_KEYS>;
    hold-trigger-on-release; // wait for other home row mods
    tapping-term-ms = <LEFT_PINKY_HOLDING_TIME>;
    quick-tap-ms = <LEFT_PINKY_REPEAT_DECAY>;
    require-prior-idle-ms = <LEFT_PINKY_STREAK_DECAY>;
    #binding-cells = <2>;
    bindings = <&kp>, <&kp>;
  };
  left_pinky_middy_bilateral: homey_left_pinky_middy_bilateral {
    compatible = "zmk,behavior-hold-tap";
    flavor = LEFT_PINKY_HOLDING_TYPE;
    hold-trigger-key-positions = <RIGHT_HAND_KEYS>;
    hold-trigger-on-release; // wait for other home row mods
    tapping-term-ms = <LEFT_PINKY_HOLDING_TIME>;
    quick-tap-ms = <LEFT_PINKY_REPEAT_DECAY>;
    require-prior-idle-ms = <LEFT_PINKY_STREAK_DECAY>;
    #binding-cells = <2>;
    bindings = <&kp>, <&left_pinky_tap>;
  };
  #define LeftPinkyMiddy left_pinky_middy_bilateral LEFT_MIDDY_MOD LEFT_MIDDY_KEY
  #ifndef LEFT_RINGY_MIDDY_HOLDING_TYPE
  #define LEFT_RINGY_MIDDY_HOLDING_TYPE LEFT_RINGY_CHORD_HOLDING_TYPE
  #endif
  #ifndef LEFT_RINGY_MIDDY_HOLDING_TIME
  #define LEFT_RINGY_MIDDY_HOLDING_TIME LEFT_RINGY_CHORD_HOLDING_TIME
  #endif
  #ifndef LEFT_RINGY_MIDDY_STREAK_DECAY
  #define LEFT_RINGY_MIDDY_STREAK_DECAY LEFT_RINGY_CHORD_STREAK_DECAY
  #endif
  #ifndef LEFT_RINGY_MIDDY_REPEAT_DECAY
  #define LEFT_RINGY_MIDDY_REPEAT_DECAY LEFT_RINGY_CHORD_REPEAT_DECAY
  #endif
  left_ringy_middy: homey_left_ringy_middy {
    compatible = "zmk,behavior-hold-tap";
    flavor = LEFT_RINGY_HOLDING_TYPE;
    hold-trigger-key-positions = <RIGHT_HAND_KEYS>;
    hold-trigger-on-release; // wait for other home row mods
    tapping-term-ms = <LEFT_RINGY_HOLDING_TIME>;
    quick-tap-ms = <LEFT_RINGY_REPEAT_DECAY>;
    require-prior-idle-ms = <LEFT_RINGY_STREAK_DECAY>;
    #binding-cells = <2>;
    bindings = <&kp>, <&kp>;
  };
  left_ringy_middy_bilateral: homey_left_ringy_middy_bilateral {
    compatible = "zmk,behavior-hold-tap";
    flavor = LEFT_RINGY_HOLDING_TYPE;
    hold-trigger-key-positions = <RIGHT_HAND_KEYS>;
    hold-trigger-on-release; // wait for other home row mods
    tapping-term-ms = <LEFT_RINGY_HOLDING_TIME>;
    quick-tap-ms = <LEFT_RINGY_REPEAT_DECAY>;
    require-prior-idle-ms = <LEFT_RINGY_STREAK_DECAY>;
    #binding-cells = <2>;
    bindings = <&kp>, <&left_ringy_tap>;
  };
  #define LeftRingyMiddy left_ringy_middy_bilateral LEFT_MIDDY_MOD LEFT_MIDDY_KEY
  #ifndef LEFT_INDEX_MIDDY_HOLDING_TYPE
  #define LEFT_INDEX_MIDDY_HOLDING_TYPE LEFT_INDEX_CHORD_HOLDING_TYPE
  #endif
  #ifndef LEFT_INDEX_MIDDY_HOLDING_TIME
  #define LEFT_INDEX_MIDDY_HOLDING_TIME LEFT_INDEX_CHORD_HOLDING_TIME
  #endif
  #ifndef LEFT_INDEX_MIDDY_STREAK_DECAY
  #define LEFT_INDEX_MIDDY_STREAK_DECAY LEFT_INDEX_CHORD_STREAK_DECAY
  #endif
  #ifndef LEFT_INDEX_MIDDY_REPEAT_DECAY
  #define LEFT_INDEX_MIDDY_REPEAT_DECAY LEFT_INDEX_CHORD_REPEAT_DECAY
  #endif
  left_index_middy: homey_left_index_middy {
    compatible = "zmk,behavior-hold-tap";
    flavor = LEFT_INDEX_HOLDING_TYPE;
    hold-trigger-key-positions = <RIGHT_HAND_KEYS>;
    hold-trigger-on-release; // wait for other home row mods
    tapping-term-ms = <LEFT_INDEX_HOLDING_TIME>;
    quick-tap-ms = <LEFT_INDEX_REPEAT_DECAY>;
    require-prior-idle-ms = <LEFT_INDEX_STREAK_DECAY>;
    #binding-cells = <2>;
    bindings = <&kp>, <&kp>;
  };
  left_index_middy_bilateral: homey_left_index_middy_bilateral {
    compatible = "zmk,behavior-hold-tap";
    flavor = LEFT_INDEX_HOLDING_TYPE;
    hold-trigger-key-positions = <RIGHT_HAND_KEYS>;
    hold-trigger-on-release; // wait for other home row mods
    tapping-term-ms = <LEFT_INDEX_HOLDING_TIME>;
    quick-tap-ms = <LEFT_INDEX_REPEAT_DECAY>;
    require-prior-idle-ms = <LEFT_INDEX_STREAK_DECAY>;
    #binding-cells = <2>;
    bindings = <&kp>, <&left_index_tap>;
  };
  #define LeftIndexMiddy left_index_middy_bilateral LEFT_MIDDY_MOD LEFT_MIDDY_KEY
  #ifndef RIGHT_PINKY_MIDDY_HOLDING_TYPE
  #define RIGHT_PINKY_MIDDY_HOLDING_TYPE RIGHT_PINKY_CHORD_HOLDING_TYPE
  #endif
  #ifndef RIGHT_PINKY_MIDDY_HOLDING_TIME
  #define RIGHT_PINKY_MIDDY_HOLDING_TIME RIGHT_PINKY_CHORD_HOLDING_TIME
  #endif
  #ifndef RIGHT_PINKY_MIDDY_STREAK_DECAY
  #define RIGHT_PINKY_MIDDY_STREAK_DECAY RIGHT_PINKY_CHORD_STREAK_DECAY
  #endif
  #ifndef RIGHT_PINKY_MIDDY_REPEAT_DECAY
  #define RIGHT_PINKY_MIDDY_REPEAT_DECAY RIGHT_PINKY_CHORD_REPEAT_DECAY
  #endif
  right_pinky_middy: homey_right_pinky_middy {
    compatible = "zmk,behavior-hold-tap";
    flavor = RIGHT_PINKY_HOLDING_TYPE;
    hold-trigger-key-positions = <LEFT_HAND_KEYS>;
    hold-trigger-on-release; // wait for other home row mods
    tapping-term-ms = <RIGHT_PINKY_HOLDING_TIME>;
    quick-tap-ms = <RIGHT_PINKY_REPEAT_DECAY>;
    require-prior-idle-ms = <RIGHT_PINKY_STREAK_DECAY>;
    #binding-cells = <2>;
    bindings = <&kp>, <&kp>;
  };
  right_pinky_middy_bilateral: homey_right_pinky_middy_bilateral {
    compatible = "zmk,behavior-hold-tap";
    flavor = RIGHT_PINKY_HOLDING_TYPE;
    hold-trigger-key-positions = <LEFT_HAND_KEYS>;
    hold-trigger-on-release; // wait for other home row mods
    tapping-term-ms = <RIGHT_PINKY_HOLDING_TIME>;
    quick-tap-ms = <RIGHT_PINKY_REPEAT_DECAY>;
    require-prior-idle-ms = <RIGHT_PINKY_STREAK_DECAY>;
    #binding-cells = <2>;
    bindings = <&kp>, <&right_pinky_tap>;
  };
  #define RightPinkyMiddy right_pinky_middy_bilateral RIGHT_MIDDY_MOD RIGHT_MIDDY_KEY
  #ifndef RIGHT_RINGY_MIDDY_HOLDING_TYPE
  #define RIGHT_RINGY_MIDDY_HOLDING_TYPE RIGHT_RINGY_CHORD_HOLDING_TYPE
  #endif
  #ifndef RIGHT_RINGY_MIDDY_HOLDING_TIME
  #define RIGHT_RINGY_MIDDY_HOLDING_TIME RIGHT_RINGY_CHORD_HOLDING_TIME
  #endif
  #ifndef RIGHT_RINGY_MIDDY_STREAK_DECAY
  #define RIGHT_RINGY_MIDDY_STREAK_DECAY RIGHT_RINGY_CHORD_STREAK_DECAY
  #endif
  #ifndef RIGHT_RINGY_MIDDY_REPEAT_DECAY
  #define RIGHT_RINGY_MIDDY_REPEAT_DECAY RIGHT_RINGY_CHORD_REPEAT_DECAY
  #endif
  right_ringy_middy: homey_right_ringy_middy {
    compatible = "zmk,behavior-hold-tap";
    flavor = RIGHT_RINGY_HOLDING_TYPE;
    hold-trigger-key-positions = <LEFT_HAND_KEYS>;
    hold-trigger-on-release; // wait for other home row mods
    tapping-term-ms = <RIGHT_RINGY_HOLDING_TIME>;
    quick-tap-ms = <RIGHT_RINGY_REPEAT_DECAY>;
    require-prior-idle-ms = <RIGHT_RINGY_STREAK_DECAY>;
    #binding-cells = <2>;
    bindings = <&kp>, <&kp>;
  };
  right_ringy_middy_bilateral: homey_right_ringy_middy_bilateral {
    compatible = "zmk,behavior-hold-tap";
    flavor = RIGHT_RINGY_HOLDING_TYPE;
    hold-trigger-key-positions = <LEFT_HAND_KEYS>;
    hold-trigger-on-release; // wait for other home row mods
    tapping-term-ms = <RIGHT_RINGY_HOLDING_TIME>;
    quick-tap-ms = <RIGHT_RINGY_REPEAT_DECAY>;
    require-prior-idle-ms = <RIGHT_RINGY_STREAK_DECAY>;
    #binding-cells = <2>;
    bindings = <&kp>, <&right_ringy_tap>;
  };
  #define RightRingyMiddy right_ringy_middy_bilateral RIGHT_MIDDY_MOD RIGHT_MIDDY_KEY
  #ifndef RIGHT_INDEX_MIDDY_HOLDING_TYPE
  #define RIGHT_INDEX_MIDDY_HOLDING_TYPE RIGHT_INDEX_CHORD_HOLDING_TYPE
  #endif
  #ifndef RIGHT_INDEX_MIDDY_HOLDING_TIME
  #define RIGHT_INDEX_MIDDY_HOLDING_TIME RIGHT_INDEX_CHORD_HOLDING_TIME
  #endif
  #ifndef RIGHT_INDEX_MIDDY_STREAK_DECAY
  #define RIGHT_INDEX_MIDDY_STREAK_DECAY RIGHT_INDEX_CHORD_STREAK_DECAY
  #endif
  #ifndef RIGHT_INDEX_MIDDY_REPEAT_DECAY
  #define RIGHT_INDEX_MIDDY_REPEAT_DECAY RIGHT_INDEX_CHORD_REPEAT_DECAY
  #endif
  right_index_middy: homey_right_index_middy {
    compatible = "zmk,behavior-hold-tap";
    flavor = RIGHT_INDEX_HOLDING_TYPE;
    hold-trigger-key-positions = <LEFT_HAND_KEYS>;
    hold-trigger-on-release; // wait for other home row mods
    tapping-term-ms = <RIGHT_INDEX_HOLDING_TIME>;
    quick-tap-ms = <RIGHT_INDEX_REPEAT_DECAY>;
    require-prior-idle-ms = <RIGHT_INDEX_STREAK_DECAY>;
    #binding-cells = <2>;
    bindings = <&kp>, <&kp>;
  };
  right_index_middy_bilateral: homey_right_index_middy_bilateral {
    compatible = "zmk,behavior-hold-tap";
    flavor = RIGHT_INDEX_HOLDING_TYPE;
    hold-trigger-key-positions = <LEFT_HAND_KEYS>;
    hold-trigger-on-release; // wait for other home row mods
    tapping-term-ms = <RIGHT_INDEX_HOLDING_TIME>;
    quick-tap-ms = <RIGHT_INDEX_REPEAT_DECAY>;
    require-prior-idle-ms = <RIGHT_INDEX_STREAK_DECAY>;
    #binding-cells = <2>;
    bindings = <&kp>, <&right_index_tap>;
  };
  #define RightIndexMiddy right_index_middy_bilateral RIGHT_MIDDY_MOD RIGHT_MIDDY_KEY
  #ifndef LEFT_PINKY_INDEX_HOLDING_TYPE
  #define LEFT_PINKY_INDEX_HOLDING_TYPE LEFT_PINKY_CHORD_HOLDING_TYPE
  #endif
  #ifndef LEFT_PINKY_INDEX_HOLDING_TIME
  #define LEFT_PINKY_INDEX_HOLDING_TIME LEFT_PINKY_CHORD_HOLDING_TIME
  #endif
  #ifndef LEFT_PINKY_INDEX_STREAK_DECAY
  #define LEFT_PINKY_INDEX_STREAK_DECAY LEFT_PINKY_CHORD_STREAK_DECAY
  #endif
  #ifndef LEFT_PINKY_INDEX_REPEAT_DECAY
  #define LEFT_PINKY_INDEX_REPEAT_DECAY LEFT_PINKY_CHORD_REPEAT_DECAY
  #endif
  left_pinky_index: homey_left_pinky_index {
    compatible = "zmk,behavior-hold-tap";
    flavor = LEFT_PINKY_HOLDING_TYPE;
    hold-trigger-key-positions = <RIGHT_HAND_KEYS>;
    hold-trigger-on-release; // wait for other home row mods
    tapping-term-ms = <LEFT_PINKY_HOLDING_TIME>;
    quick-tap-ms = <LEFT_PINKY_REPEAT_DECAY>;
    require-prior-idle-ms = <LEFT_PINKY_STREAK_DECAY>;
    #binding-cells = <2>;
    bindings = <&kp>, <&kp>;
  };
  left_pinky_index_bilateral: homey_left_pinky_index_bilateral {
    compatible = "zmk,behavior-hold-tap";
    flavor = LEFT_PINKY_HOLDING_TYPE;
    hold-trigger-key-positions = <RIGHT_HAND_KEYS>;
    hold-trigger-on-release; // wait for other home row mods
    tapping-term-ms = <LEFT_PINKY_HOLDING_TIME>;
    quick-tap-ms = <LEFT_PINKY_REPEAT_DECAY>;
    require-prior-idle-ms = <LEFT_PINKY_STREAK_DECAY>;
    #binding-cells = <2>;
    bindings = <&kp>, <&left_pinky_tap>;
  };
  #define LeftPinkyIndex left_pinky_index_bilateral LEFT_INDEX_MOD LEFT_INDEX_KEY
  #ifndef LEFT_RINGY_INDEX_HOLDING_TYPE
  #define LEFT_RINGY_INDEX_HOLDING_TYPE LEFT_RINGY_CHORD_HOLDING_TYPE
  #endif
  #ifndef LEFT_RINGY_INDEX_HOLDING_TIME
  #define LEFT_RINGY_INDEX_HOLDING_TIME LEFT_RINGY_CHORD_HOLDING_TIME
  #endif
  #ifndef LEFT_RINGY_INDEX_STREAK_DECAY
  #define LEFT_RINGY_INDEX_STREAK_DECAY LEFT_RINGY_CHORD_STREAK_DECAY
  #endif
  #ifndef LEFT_RINGY_INDEX_REPEAT_DECAY
  #define LEFT_RINGY_INDEX_REPEAT_DECAY LEFT_RINGY_CHORD_REPEAT_DECAY
  #endif
  left_ringy_index: homey_left_ringy_index {
    compatible = "zmk,behavior-hold-tap";
    flavor = LEFT_RINGY_HOLDING_TYPE;
    hold-trigger-key-positions = <RIGHT_HAND_KEYS>;
    hold-trigger-on-release; // wait for other home row mods
    tapping-term-ms = <LEFT_RINGY_HOLDING_TIME>;
    quick-tap-ms = <LEFT_RINGY_REPEAT_DECAY>;
    require-prior-idle-ms = <LEFT_RINGY_STREAK_DECAY>;
    #binding-cells = <2>;
    bindings = <&kp>, <&kp>;
  };
  left_ringy_index_bilateral: homey_left_ringy_index_bilateral {
    compatible = "zmk,behavior-hold-tap";
    flavor = LEFT_RINGY_HOLDING_TYPE;
    hold-trigger-key-positions = <RIGHT_HAND_KEYS>;
    hold-trigger-on-release; // wait for other home row mods
    tapping-term-ms = <LEFT_RINGY_HOLDING_TIME>;
    quick-tap-ms = <LEFT_RINGY_REPEAT_DECAY>;
    require-prior-idle-ms = <LEFT_RINGY_STREAK_DECAY>;
    #binding-cells = <2>;
    bindings = <&kp>, <&left_ringy_tap>;
  };
  #define LeftRingyIndex left_ringy_index_bilateral LEFT_INDEX_MOD LEFT_INDEX_KEY
  #ifndef LEFT_MIDDY_INDEX_HOLDING_TYPE
  #define LEFT_MIDDY_INDEX_HOLDING_TYPE LEFT_MIDDY_CHORD_HOLDING_TYPE
  #endif
  #ifndef LEFT_MIDDY_INDEX_HOLDING_TIME
  #define LEFT_MIDDY_INDEX_HOLDING_TIME LEFT_MIDDY_CHORD_HOLDING_TIME
  #endif
  #ifndef LEFT_MIDDY_INDEX_STREAK_DECAY
  #define LEFT_MIDDY_INDEX_STREAK_DECAY LEFT_MIDDY_CHORD_STREAK_DECAY
  #endif
  #ifndef LEFT_MIDDY_INDEX_REPEAT_DECAY
  #define LEFT_MIDDY_INDEX_REPEAT_DECAY LEFT_MIDDY_CHORD_REPEAT_DECAY
  #endif
  left_middy_index: homey_left_middy_index {
    compatible = "zmk,behavior-hold-tap";
    flavor = LEFT_MIDDY_HOLDING_TYPE;
    hold-trigger-key-positions = <RIGHT_HAND_KEYS>;
    hold-trigger-on-release; // wait for other home row mods
    tapping-term-ms = <LEFT_MIDDY_HOLDING_TIME>;
    quick-tap-ms = <LEFT_MIDDY_REPEAT_DECAY>;
    require-prior-idle-ms = <LEFT_MIDDY_STREAK_DECAY>;
    #binding-cells = <2>;
    bindings = <&kp>, <&kp>;
  };
  left_middy_index_bilateral: homey_left_middy_index_bilateral {
    compatible = "zmk,behavior-hold-tap";
    flavor = LEFT_MIDDY_HOLDING_TYPE;
    hold-trigger-key-positions = <RIGHT_HAND_KEYS>;
    hold-trigger-on-release; // wait for other home row mods
    tapping-term-ms = <LEFT_MIDDY_HOLDING_TIME>;
    quick-tap-ms = <LEFT_MIDDY_REPEAT_DECAY>;
    require-prior-idle-ms = <LEFT_MIDDY_STREAK_DECAY>;
    #binding-cells = <2>;
    bindings = <&kp>, <&left_middy_tap>;
  };
  #define LeftMiddyIndex left_middy_index_bilateral LEFT_INDEX_MOD LEFT_INDEX_KEY
  #ifndef RIGHT_PINKY_INDEX_HOLDING_TYPE
  #define RIGHT_PINKY_INDEX_HOLDING_TYPE RIGHT_PINKY_CHORD_HOLDING_TYPE
  #endif
  #ifndef RIGHT_PINKY_INDEX_HOLDING_TIME
  #define RIGHT_PINKY_INDEX_HOLDING_TIME RIGHT_PINKY_CHORD_HOLDING_TIME
  #endif
  #ifndef RIGHT_PINKY_INDEX_STREAK_DECAY
  #define RIGHT_PINKY_INDEX_STREAK_DECAY RIGHT_PINKY_CHORD_STREAK_DECAY
  #endif
  #ifndef RIGHT_PINKY_INDEX_REPEAT_DECAY
  #define RIGHT_PINKY_INDEX_REPEAT_DECAY RIGHT_PINKY_CHORD_REPEAT_DECAY
  #endif
  right_pinky_index: homey_right_pinky_index {
    compatible = "zmk,behavior-hold-tap";
    flavor = RIGHT_PINKY_HOLDING_TYPE;
    hold-trigger-key-positions = <LEFT_HAND_KEYS>;
    hold-trigger-on-release; // wait for other home row mods
    tapping-term-ms = <RIGHT_PINKY_HOLDING_TIME>;
    quick-tap-ms = <RIGHT_PINKY_REPEAT_DECAY>;
    require-prior-idle-ms = <RIGHT_PINKY_STREAK_DECAY>;
    #binding-cells = <2>;
    bindings = <&kp>, <&kp>;
  };
  right_pinky_index_bilateral: homey_right_pinky_index_bilateral {
    compatible = "zmk,behavior-hold-tap";
    flavor = RIGHT_PINKY_HOLDING_TYPE;
    hold-trigger-key-positions = <LEFT_HAND_KEYS>;
    hold-trigger-on-release; // wait for other home row mods
    tapping-term-ms = <RIGHT_PINKY_HOLDING_TIME>;
    quick-tap-ms = <RIGHT_PINKY_REPEAT_DECAY>;
    require-prior-idle-ms = <RIGHT_PINKY_STREAK_DECAY>;
    #binding-cells = <2>;
    bindings = <&kp>, <&right_pinky_tap>;
  };
  #define RightPinkyIndex right_pinky_index_bilateral RIGHT_INDEX_MOD RIGHT_INDEX_KEY
  #ifndef RIGHT_RINGY_INDEX_HOLDING_TYPE
  #define RIGHT_RINGY_INDEX_HOLDING_TYPE RIGHT_RINGY_CHORD_HOLDING_TYPE
  #endif
  #ifndef RIGHT_RINGY_INDEX_HOLDING_TIME
  #define RIGHT_RINGY_INDEX_HOLDING_TIME RIGHT_RINGY_CHORD_HOLDING_TIME
  #endif
  #ifndef RIGHT_RINGY_INDEX_STREAK_DECAY
  #define RIGHT_RINGY_INDEX_STREAK_DECAY RIGHT_RINGY_CHORD_STREAK_DECAY
  #endif
  #ifndef RIGHT_RINGY_INDEX_REPEAT_DECAY
  #define RIGHT_RINGY_INDEX_REPEAT_DECAY RIGHT_RINGY_CHORD_REPEAT_DECAY
  #endif
  right_ringy_index: homey_right_ringy_index {
    compatible = "zmk,behavior-hold-tap";
    flavor = RIGHT_RINGY_HOLDING_TYPE;
    hold-trigger-key-positions = <LEFT_HAND_KEYS>;
    hold-trigger-on-release; // wait for other home row mods
    tapping-term-ms = <RIGHT_RINGY_HOLDING_TIME>;
    quick-tap-ms = <RIGHT_RINGY_REPEAT_DECAY>;
    require-prior-idle-ms = <RIGHT_RINGY_STREAK_DECAY>;
    #binding-cells = <2>;
    bindings = <&kp>, <&kp>;
  };
  right_ringy_index_bilateral: homey_right_ringy_index_bilateral {
    compatible = "zmk,behavior-hold-tap";
    flavor = RIGHT_RINGY_HOLDING_TYPE;
    hold-trigger-key-positions = <LEFT_HAND_KEYS>;
    hold-trigger-on-release; // wait for other home row mods
    tapping-term-ms = <RIGHT_RINGY_HOLDING_TIME>;
    quick-tap-ms = <RIGHT_RINGY_REPEAT_DECAY>;
    require-prior-idle-ms = <RIGHT_RINGY_STREAK_DECAY>;
    #binding-cells = <2>;
    bindings = <&kp>, <&right_ringy_tap>;
  };
  #define RightRingyIndex right_ringy_index_bilateral RIGHT_INDEX_MOD RIGHT_INDEX_KEY
  #ifndef RIGHT_MIDDY_INDEX_HOLDING_TYPE
  #define RIGHT_MIDDY_INDEX_HOLDING_TYPE RIGHT_MIDDY_CHORD_HOLDING_TYPE
  #endif
  #ifndef RIGHT_MIDDY_INDEX_HOLDING_TIME
  #define RIGHT_MIDDY_INDEX_HOLDING_TIME RIGHT_MIDDY_CHORD_HOLDING_TIME
  #endif
  #ifndef RIGHT_MIDDY_INDEX_STREAK_DECAY
  #define RIGHT_MIDDY_INDEX_STREAK_DECAY RIGHT_MIDDY_CHORD_STREAK_DECAY
  #endif
  #ifndef RIGHT_MIDDY_INDEX_REPEAT_DECAY
  #define RIGHT_MIDDY_INDEX_REPEAT_DECAY RIGHT_MIDDY_CHORD_REPEAT_DECAY
  #endif
  right_middy_index: homey_right_middy_index {
    compatible = "zmk,behavior-hold-tap";
    flavor = RIGHT_MIDDY_HOLDING_TYPE;
    hold-trigger-key-positions = <LEFT_HAND_KEYS>;
    hold-trigger-on-release; // wait for other home row mods
    tapping-term-ms = <RIGHT_MIDDY_HOLDING_TIME>;
    quick-tap-ms = <RIGHT_MIDDY_REPEAT_DECAY>;
    require-prior-idle-ms = <RIGHT_MIDDY_STREAK_DECAY>;
    #binding-cells = <2>;
    bindings = <&kp>, <&kp>;
  };
  right_middy_index_bilateral: homey_right_middy_index_bilateral {
    compatible = "zmk,behavior-hold-tap";
    flavor = RIGHT_MIDDY_HOLDING_TYPE;
    hold-trigger-key-positions = <LEFT_HAND_KEYS>;
    hold-trigger-on-release; // wait for other home row mods
    tapping-term-ms = <RIGHT_MIDDY_HOLDING_TIME>;
    quick-tap-ms = <RIGHT_MIDDY_REPEAT_DECAY>;
    require-prior-idle-ms = <RIGHT_MIDDY_STREAK_DECAY>;
    #binding-cells = <2>;
    bindings = <&kp>, <&right_middy_tap>;
  };
  #define RightMiddyIndex right_middy_index_bilateral RIGHT_INDEX_MOD RIGHT_INDEX_KEY

  //
  // Thumb cluster hold-tap keys for Miryoku layers
  //
  thumb: thumb_layer_access {
    compatible = "zmk,behavior-hold-tap";
    flavor = THUMB_HOLDING_TYPE;
    tapping-term-ms = <THUMB_HOLDING_TIME>;
    quick-tap-ms = <THUMB_REPEAT_DECAY>; // enable repeat
    #binding-cells = <2>;
    bindings = <&mo>, <&kp>;
    #ifdef THUMB_FORGIVENESS
    retro-tap; // tap on standalone hold
    #endif
  };
  stumb: thumb_layer_access_sticky_key_oneshot {
    compatible = "zmk,behavior-hold-tap";
    flavor = THUMB_HOLDING_TYPE;
    tapping-term-ms = <THUMB_HOLDING_TIME>;
    quick-tap-ms = <THUMB_REPEAT_DECAY>; // enable repeat
    #binding-cells = <2>;
    bindings = <&mo>, <&sticky_key_oneshot>;
  };
  crumb: thumb_layer_access_retro_tap {
    compatible = "zmk,behavior-hold-tap";
    flavor = THUMB_HOLDING_TYPE;
    tapping-term-ms = <THUMB_HOLDING_TIME>;
    quick-tap-ms = <THUMB_REPEAT_DECAY>; // enable repeat
    #binding-cells = <2>;
    bindings = <&mo>, <&kp>;
    retro-tap; // tap on standalone hold
  };
  crumb_parang_left: crumb_layer_access_parang_left {
    compatible = "zmk,behavior-hold-tap";
    flavor = THUMB_HOLDING_TYPE;
    tapping-term-ms = <THUMB_HOLDING_TIME>;
    quick-tap-ms = <THUMB_REPEAT_DECAY>; // enable repeat
    #binding-cells = <2>;
    bindings = <&mo>, <&parang_left>;
    retro-tap; // tap on standalone hold
  };
  crumb_parang_right: crumb_layer_access_parang_right {
    compatible = "zmk,behavior-hold-tap";
    flavor = THUMB_HOLDING_TYPE;
    tapping-term-ms = <THUMB_HOLDING_TIME>;
    quick-tap-ms = <THUMB_REPEAT_DECAY>; // enable repeat
    #binding-cells = <2>;
    bindings = <&mo>, <&parang_right>;
    retro-tap; // tap on standalone hold
  };
  space: thumb_layer_access_spacebar {
    compatible = "zmk,behavior-hold-tap";
    flavor = SPACE_HOLDING_TYPE;
    tapping-term-ms = <SPACE_HOLDING_TIME>;
    quick-tap-ms = <SPACE_REPEAT_DECAY>; // enable repeat
    #binding-cells = <2>;
    bindings = <&mo>, <&kp>;
    #ifdef SPACE_FORGIVENESS
    retro-tap; // tap on standalone hold
    #endif
  };

  //
  // Shift + LEFT_PARENTHESIS = LESS_THAN
  //
  parang_left: left_parenthesis_and_less_than {
    compatible = "zmk,behavior-mod-morph";
    #binding-cells = <0>;
    bindings = <&kp LPAR>, <&kp LT>;
    mods = <(MOD_LSFT|MOD_RSFT)>;
  };

  //
  // Shift + RIGHT_PARENTHESIS = GREATER_THAN
  //
  parang_right: right_parenthesis_and_greater_than {
    compatible = "zmk,behavior-mod-morph";
    #binding-cells = <0>;
    bindings = <&kp RPAR>, <&kp GT>;
    mods = <(MOD_LSFT|MOD_RSFT)>;
  };

  //////////////////////////////////////////////////////////////////////////
  //
  // &sk (sticky key) variant that is truly one-shot
  //
  //////////////////////////////////////////////////////////////////////////

  //
  // STICKY_1SHOT_DECAY defines how much time you have left (milliseconds)
  // after tapping a sticky key before it expires (won't apply to next tap).
  //
  #ifndef STICKY_1SHOT_DECAY
  #define STICKY_1SHOT_DECAY 500
  #endif

  //
  // STICKY_HOLDING_TIME defines how long you need to hold (milliseconds)
  // sticky one-shot keys in order to trigger their hold (not tap) action.
  //
  #ifndef STICKY_HOLDING_TIME
  #define STICKY_HOLDING_TIME (TAPPING_RESOLUTION + 50)
  #endif

  sticky_key_modtap: sticky_key_modtap {
    compatible = "zmk,behavior-hold-tap";
    flavor = "tap-preferred";
    tapping-term-ms = <STICKY_HOLDING_TIME>;
    #binding-cells = <2>;
    bindings = <&kp>, <&sticky_key_oneshot>;
  };
  sticky_key_oneshot: sticky_key_oneshot_macro {
    compatible = "zmk,behavior-macro-one-param";
    wait-ms = <0>;
    tap-ms = <0>;
    #binding-cells = <1>;
    bindings
      = <&macro_param_1to1>
      , <&macro_tap &sticky_key_quickrel MACRO_PLACEHOLDER>
      ;
  };
  sticky_key_quickrel: sticky_key_quick_release {
    compatible = "zmk,behavior-sticky-key";
    #binding-cells = <1>;
    bindings = <&kp>;
    release-after-ms = <STICKY_1SHOT_DECAY>;
    quick-release;
    ignore-modifiers;
  };

  //////////////////////////////////////////////////////////////////////////
  //
  // ZMK global overrides
  //
  //////////////////////////////////////////////////////////////////////////

  //
  // CapsWord - ported from Pascal Getreuer's extension for QMK
  // - https://zmk.dev/docs/behaviors/caps-word
  // - https://getreuer.info/posts/keyboards/caps-word/index.html
  //
  caps_word {
    continue-list = <
      UNDERSCORE MINUS
      BACKSPACE DELETE
      N1 N2 N3 N4 N5 N6 N7 N8 N9 N0
    >;
  };


  //
  // Magic hold-tap: hold for Magic layer, tap for no-op
  // (Glove80 original taps rgb_ug_status_macro; Adv360 has no equivalent)
  //
  magic: magic {
    compatible = "zmk,behavior-hold-tap";
    #binding-cells = <2>;
    flavor = "tap-preferred";
    tapping-term-ms = <200>;
    bindings = <&mo>, <&none>;
  };

};

macros {

  ZMK_MACRO(dot_dot,
    wait-ms = <0>;
    tap-ms = <0>;
    bindings = <&macro_tap &kp DOT &kp DOT>;
  )

  ZMK_MACRO(triple_backtick,
    wait-ms = <0>;
    tap-ms = <0>;
    bindings = <&macro_tap &kp GRAVE &kp GRAVE &kp GRAVE>;
  )

  //
  // Linux Magic System Request Key - hold this down and type REISUB
  // - https://www.kernel.org/doc/html/latest/admin-guide/sysrq.html
  // - https://github.com/manna-harbour/miryoku/discussions/259
  // - https://unix.stackexchange.com/a/143955 (use LALT, not RALT)
  //
  ZMK_MACRO(linux_magic_sysrq,
    wait-ms = <0>;
    tap-ms = <0>;
    bindings
      = <&macro_press &mo 0 &kp LALT>
      , <&macro_tap &kp PRINTSCREEN>
      , <&macro_pause_for_release>
      , <&macro_release &mo 0 &kp LALT>
      ;
  )

  //
  // Mod+Tab application switcher - hold this down to keep menu open
  //
  mod_tab: mod_tab_switcher {
    compatible = "zmk,behavior-macro-one-param";
    wait-ms = <0>;
    tap-ms = <0>;
    #binding-cells = <1>;
    bindings
      = <&macro_param_1to1>
      , <&macro_press &kp MACRO_PLACEHOLDER>
      , <&macro_tap &kp TAB>
      , <&macro_pause_for_release>
      , <&macro_param_1to1>
      , <&macro_release &kp MACRO_PLACEHOLDER>
      ;
  };
  mod_tab_chord: mod_tab_switcher_chord {
    compatible = "zmk,behavior-macro-two-param";
    wait-ms = <0>;
    tap-ms = <0>;
    #binding-cells = <2>;
    bindings
      = <&macro_param_2to1>
      , <&macro_press &mo MACRO_PLACEHOLDER>
      , <&macro_param_1to1>
      , <&macro_press &mod_tab MACRO_PLACEHOLDER>
      , <&macro_pause_for_release>
      , <&macro_param_1to1>
      , <&macro_release &mod_tab MACRO_PLACEHOLDER>
      , <&macro_param_2to1>
      , <&macro_release &mo MACRO_PLACEHOLDER>
      ;
  };

  //////////////////////////////////////////////////////////////////////////
  //
  // Approximation of Pascal Getreuer's Select Word macro from QMK
  // - https://getreuer.info/posts/keyboards/select-word/index.html
  //
  //////////////////////////////////////////////////////////////////////////

  //
  // SELECT_WORD_DELAY defines how long the macro waits (milliseconds)
  // after moving the cursor before it selects a word.  A larger delay
  // may allow the macro to move to the next word upon each invocation.
  //
  #ifndef SELECT_WORD_DELAY
  #define SELECT_WORD_DELAY 1
  #endif

  #define select_all kp _C(A)

  ZMK_MACRO(select_none,
    wait-ms = <SELECT_WORD_DELAY>;
    tap-ms = <SELECT_WORD_DELAY>;
    bindings = <&kp DOWN &kp UP &kp RIGHT &kp LEFT>;
  )

  //
  // select a word (jumps to next word upon each successive invocation)
  //
  select_word: select_word {
    compatible = "zmk,behavior-mod-morph";
    #binding-cells = <0>;
    bindings = <&select_word_right>, <&select_word_left>;
    mods = <(MOD_LSFT|MOD_RSFT)>;
  };
  ZMK_MACRO(select_word_right,
    wait-ms = <SELECT_WORD_DELAY>;
    tap-ms = <SELECT_WORD_DELAY>;
    bindings = <&kp _WORD(RIGHT) &kp _WORD(LEFT) &kp _WORD(LS(RIGHT))>;
  )
  ZMK_MACRO(select_word_left,
    wait-ms = <SELECT_WORD_DELAY>;
    tap-ms = <SELECT_WORD_DELAY>;
    bindings = <&kp _WORD(LEFT) &kp _WORD(RIGHT) &kp _WORD(LS(LEFT))>;
  )

  //
  // extend current selection by one word
  //
  extend_word: extend_word {
    compatible = "zmk,behavior-mod-morph";
    #binding-cells = <0>;
    bindings = <&extend_word_right>, <&extend_word_left>;
    mods = <(MOD_LSFT|MOD_RSFT)>;
  };
  ZMK_MACRO(extend_word_right,
    wait-ms = <SELECT_WORD_DELAY>;
    tap-ms = <SELECT_WORD_DELAY>;
    bindings = <&kp _WORD(LS(RIGHT))>;
  )
  ZMK_MACRO(extend_word_left,
    wait-ms = <SELECT_WORD_DELAY>;
    tap-ms = <SELECT_WORD_DELAY>;
    bindings = <&kp _WORD(LS(LEFT))>;
  )

  //
  // select current line
  //
  select_line: select_line {
    compatible = "zmk,behavior-mod-morph";
    #binding-cells = <0>;
    bindings = <&select_line_right>, <&select_line_left>;
    mods = <(MOD_LSFT|MOD_RSFT)>;
  };
  ZMK_MACRO(select_line_right,
    wait-ms = <SELECT_WORD_DELAY>;
    tap-ms = <SELECT_WORD_DELAY>;
    bindings = <&kp _HOME &kp LS(_END)>;
  )
  ZMK_MACRO(select_line_left,
    wait-ms = <SELECT_WORD_DELAY>;
    tap-ms = <SELECT_WORD_DELAY>;
    bindings = <&kp _END &kp LS(_HOME)>;
  )

  //
  // extend current selection by one line
  //
  extend_line: extend_line {
    compatible = "zmk,behavior-mod-morph";
    #binding-cells = <0>;
    bindings = <&extend_line_right>, <&extend_line_left>;
    mods = <(MOD_LSFT|MOD_RSFT)>;
  };
  ZMK_MACRO(extend_line_right,
    wait-ms = <SELECT_WORD_DELAY>;
    tap-ms = <SELECT_WORD_DELAY>;
    bindings = <&kp LS(DOWN) &kp LS(_END)>;
  )
  ZMK_MACRO(extend_line_left,
    wait-ms = <SELECT_WORD_DELAY>;
    tap-ms = <SELECT_WORD_DELAY>;
    bindings = <&kp LS(UP) &kp LS(_HOME)>;
  )

  //////////////////////////////////////////////////////////////////////////
  //
  // World layer - international characters
  //
  //////////////////////////////////////////////////////////////////////////

  //
  // WORLD_USE_COMPOSE uses OS-native Compose keycodes instead of Unicode
  // for characters in the "compositions" section of the `world.yaml` file.
  //
  // NOTE: keep this setting disabled when using UnicodeHexInput in macOS
  // to avoid inconsistent behavior when typing World vs Emoji layer keys.
  //
  //#define WORLD_USE_COMPOSE

  //
  // WORLD_HOST_AZERTY indicates that your computer is set to AZERTY locale.
  //
  //#define WORLD_HOST_AZERTY
  #ifdef WORLD_HOST_AZERTY
    #define WORLD_SHIFT_NUMBER
    #define _NA Q
  #endif

  //
  // WORLD_SHIFT_NUMBER indicates that Shift must be applied when typing out
  // digits from the number row, which is needed for locales such as AZERTY.
  //
  //#define WORLD_SHIFT_NUMBER
  #ifdef WORLD_SHIFT_NUMBER
    #define _N0 LS(N0)
    #define _N1 LS(N1)
    #define _N2 LS(N2)
    #define _N3 LS(N3)
    #define _N4 LS(N4)
    #define _N5 LS(N5)
    #define _N6 LS(N6)
    #define _N7 LS(N7)
    #define _N8 LS(N8)
    #define _N9 LS(N9)
  #endif

  //
  // UNICODE_TAP_DELAY defines how long the macro waits (milliseconds)
  // between keystrokes while inputting the Unicode codepoint shortcut.
  //
  #ifndef UNICODE_TAP_DELAY
  #define UNICODE_TAP_DELAY 1
  #endif

  //
  // UNICODE_SEQ_DELAY defines how long the macro waits (milliseconds)
  // between emitting Unicode codepoints in multi-codepoint characters.
  //
  #ifndef UNICODE_SEQ_DELAY
  #define UNICODE_SEQ_DELAY 10
  #endif

  #define UNICODE(name, ...) \
    ZMK_MACRO(name, \
      wait-ms = <UNICODE_TAP_DELAY>; \
      tap-ms = <UNICODE_TAP_DELAY>; \
      bindings = __VA_ARGS__; \
    )

  //
  // UNICODE_SEQ_LINUX() specifies how Unicode hexadecimal codepoint
  // keystrokes are transformed into Unicode characters under Linux.
  //
  #ifndef UNICODE_SEQ_LINUX
  #define UNICODE_SEQ_LINUX(keystrokes) \
    <&macro_tap &kp LC(LS(U)) keystrokes &kp ENTER>
  #endif

  //
  // UNICODE_SEQ_MACOS() specifies how Unicode hexadecimal codepoint
  // keystrokes are transformed into Unicode characters under macOS.
  //
  #ifndef UNICODE_SEQ_MACOS
  #define UNICODE_SEQ_MACOS(keystrokes) \
    <&macro_press &kp LALT> ,\
    <&macro_tap keystrokes> ,\
    <&macro_release &kp LALT>
  #endif

  //
  // UNICODE_SEQ_WINDOWS() specifies how Unicode hexadecimal codepoint
  // keystrokes are transformed into Unicode characters under Windows.
  //
  // If you've configured WinCompose to use a different trigger hotkey,
  // such as F13 instead of the default RA(U) shortcut, simply override
  // this definition to adapt all UNICODE() function calls accordingly.
  //
  #ifndef UNICODE_SEQ_WINDOWS
  #define UNICODE_SEQ_WINDOWS(keystrokes) \
    <&macro_tap &kp RALT &kp U keystrokes &kp ENTER>
  #endif

  //
  // COMPOSE_KEY_LINUX specifies the keycode for Compose key in Linux,
  // which may be RALT by default but can be reconfigured as follows:
  //
  // $ setxkbmap -option compose:sclk # use ScrollLock as Compose key
  //
  // See xkeyboard-config(7) for possible choices for the Compose key:
  // https://manpages.debian.org/stable/xkb-data/xkeyboard-config.7.en.html#Position_of_Compose_key
  //
  // #define COMPOSE_KEY_LINUX RALT            // compose:ralt
  // #define COMPOSE_KEY_LINUX LGUI            // compose:lwin
  // #define COMPOSE_KEY_LINUX RA(LGUI)        // compose:lwin-altgr
  // #define COMPOSE_KEY_LINUX RGUI            // compose:rwin
  // #define COMPOSE_KEY_LINUX RA(RGUI)        // compose:rwin-altgr
  // #define COMPOSE_KEY_LINUX K_MENU          // compose:menu
  // #define COMPOSE_KEY_LINUX RA(K_MENU)      // compose:menu-altgr
  // #define COMPOSE_KEY_LINUX LCTL            // compose:lctrl
  // #define COMPOSE_KEY_LINUX RA(LCTL)        // compose:lctrl-altgr
  // #define COMPOSE_KEY_LINUX RCTL            // compose:rctrl
  // #define COMPOSE_KEY_LINUX RA(RCTL)        // compose:rctrl-altgr
  // #define COMPOSE_KEY_LINUX CAPS            // compose:caps
  // #define COMPOSE_KEY_LINUX RA(CAPS)        // compose:caps-altgr
  // #define COMPOSE_KEY_LINUX NON_US_BSLH     // compose:102
  // #define COMPOSE_KEY_LINUX RA(NON_US_BSLH) // compose:102-altgr
  // #define COMPOSE_KEY_LINUX PAUSE_BREAK     // compose:paus
  // #define COMPOSE_KEY_LINUX PSCRN           // compose:prsc
  // #define COMPOSE_KEY_LINUX SLCK            // compose:sclk
  //
  #ifndef COMPOSE_KEY_LINUX
  #define COMPOSE_KEY_LINUX RALT
  #endif

  //
  // COMPOSE_SEQ_LINUX() prefixes keystrokes with the Linux Compose key.
  //
  #ifndef COMPOSE_SEQ_LINUX
  #define COMPOSE_SEQ_LINUX(keystrokes) \
    <&macro_tap &kp COMPOSE_KEY_LINUX keystrokes>
  #endif

  //
  // COMPOSE_SEQ_MACOS() formats keystrokes for macOS character entry.
  //
  #ifndef COMPOSE_SEQ_MACOS
  #define COMPOSE_SEQ_MACOS(keystrokes) \
    <&macro_tap keystrokes>
  #endif

  //
  // COMPOSE_SEQ_WINDOWS() wraps keystrokes in Windows AltCode sequence.
  //
  #ifndef COMPOSE_SEQ_WINDOWS
  #define COMPOSE_SEQ_WINDOWS(keystrokes) \
    <&macro_press &kp LALT>, \
    <&macro_tap keystrokes>, \
    <&macro_release &kp LALT>
  #endif
  #if OPERATING_SYSTEM == 'L'
    #define UNICODE_MORPH_MODS (MOD_LCTL|MOD_LSFT)
  #elif OPERATING_SYSTEM == 'M'
    #define UNICODE_MORPH_MODS MOD_LALT
  #elif OPERATING_SYSTEM == 'W'
    #define UNICODE_MORPH_MODS MOD_RALT
  #endif
  #if OPERATING_SYSTEM == 'L'
    // $ grep "compose:" /usr/share/X11/xkb/rules/base.lst
    // compose:ralt         Right Alt
    #if COMPOSE_KEY_LINUX == RALT
      #define COMPOSE_MORPH_MODS MOD_RALT
    // compose:lwin         Left Win
    #elif COMPOSE_KEY_LINUX == LGUI
      #define COMPOSE_MORPH_MODS MOD_LGUI
    // compose:lwin-altgr   3rd level of Left Win
    #elif COMPOSE_KEY_LINUX == RA(LGUI)
      #define COMPOSE_MORPH_MODS (MOD_LGUI|MOD_RALT)
    // compose:rwin         Right Win
    #elif COMPOSE_KEY_LINUX == RGUI
      #define COMPOSE_MORPH_MODS MOD_RGUI
    // compose:rwin-altgr   3rd level of Right Win
    #elif COMPOSE_KEY_LINUX == RA(RGUI)
      #define COMPOSE_MORPH_MODS (MOD_RGUI|MOD_RALT)
    // compose:menu         Menu
    // compose:menu-altgr   3rd level of Menu
    #elif COMPOSE_KEY_LINUX == RA(K_MENU)
      #define COMPOSE_MORPH_MODS MOD_RALT
    // compose:lctrl        Left Ctrl
    #elif COMPOSE_KEY_LINUX == LCTL
      #define COMPOSE_MORPH_MODS MOD_LCTL
    // compose:lctrl-altgr  3rd level of Left Ctrl
    #elif COMPOSE_KEY_LINUX == RA(LCTL)
      #define COMPOSE_MORPH_MODS (MOD_LCTL|MOD_RALT)
    // compose:rctrl        Right Ctrl
    #elif COMPOSE_KEY_LINUX == RCTL
      #define COMPOSE_MORPH_MODS MOD_RCTL
    // compose:rctrl-altgr  3rd level of Right Ctrl
    #elif COMPOSE_KEY_LINUX == RA(RCTL)
      #define COMPOSE_MORPH_MODS (MOD_RCTL|MOD_RALT)
    // compose:caps         Caps Lock
    // compose:caps-altgr   3rd level of Caps Lock
    #elif COMPOSE_KEY_LINUX == RA(CAPS)
      #define COMPOSE_MORPH_MODS MOD_RALT
    // compose:102          The "&lt; &gt;" key
    // compose:102-altgr    3rd level of the "&lt; &gt;" key
    #elif COMPOSE_KEY_LINUX == RA(NON_US_BSLH)
      #define COMPOSE_MORPH_MODS MOD_RALT
    // compose:paus         Pause
    // compose:prsc         PrtSc
    // compose:sclk         Scroll Lock
    #else
      #define COMPOSE_MORPH_MODS 0
    #endif
  #elif OPERATING_SYSTEM == 'M'
    #define COMPOSE_MORPH_MODS 0
  #elif OPERATING_SYSTEM == 'W'
    #define COMPOSE_MORPH_MODS MOD_LALT
  #endif
  #ifndef _N0
  #define _N0 N0
  #endif
  #ifndef _N1
  #define _N1 N1
  #endif
  #ifndef _N2
  #define _N2 N2
  #endif
  #ifndef _N3
  #define _N3 N3
  #endif
  #ifndef _N4
  #define _N4 N4
  #endif
  #ifndef _N5
  #define _N5 N5
  #endif
  #ifndef _N6
  #define _N6 N6
  #endif
  #ifndef _N7
  #define _N7 N7
  #endif
  #ifndef _N8
  #define _N8 N8
  #endif
  #ifndef _N9
  #define _N9 N9
  #endif
  #ifndef _NA
  #define _NA A
  #endif
  #ifndef _NB
  #define _NB B
  #endif
  #ifndef _NC
  #define _NC C
  #endif
  #ifndef _ND
  #define _ND D
  #endif
  #ifndef _NE
  #define _NE E
  #endif
  #ifndef _NF
  #define _NF F
  #endif

  //

};
}; // close / { root DTS node

//////////////////////////////////////////////////////////////////////////
//
// World layer + Emoji layer Unicode macros
// Generated from world.yaml and emoji.yaml by generate_unicode.rb
// (Has its own / { macros {} }; block and emoji presets at root level)
//
//////////////////////////////////////////////////////////////////////////

#include "unicode_macros.dtsi"


//
// Mouse key constants and configuration
//

//////////////////////////////////////////////////////////////////////////
//
// Mouse keys (keyboard mouse control) requires v24.12 firmware or newer:
// override the "HID_POINTING" setting to "y" in Advanced Configuration
// and then select "v24.12" firmware from the drop-down menu located at
// Glove80 Layout Editor > Settings > Advanced Settings > Firmware Version
//
// Alternatively, you can use either PR36 or PR23 beta firmware for this:
// select "community.pr36.mouse-keys" from the drop-down menu located at
// Glove80 Layout Editor > Settings > Advanced Settings > Firmware Version
//
// - https://github.com/moergo-sc/zmk/pull/36
// - https://github.com/moergo-sc/zmk/pull/23
// - https://gist.github.com/krissen/dd27082e7ab0575619c7a31f4d2ec7ae
// - https://github.com/zmkfirmware/zmk/compare/main...urob:zmk:mouse-3.2
// - https://github.com/caksoylar/zmk-config/commit/0020c23c544cd7111013f0114609d1fb90e0e475
// - https://github.com/caksoylar/zmk-config/commit/e35ee2f08788927683df7bbdd7fc73434473886e
//
//////////////////////////////////////////////////////////////////////////

//
// NATURAL_SCROLLING reverses the directionality of the mouse scroll wheel
// to support "natural scrolling" in macOS and other desktop environments.
//
//#define NATURAL_SCROLLING

#ifdef NATURAL_SCROLLING
  #define MOUSE_SCROLL_UP    SCRL_DOWN
  #define MOUSE_SCROLL_DOWN  SCRL_UP
  #define MOUSE_SCROLL_LEFT  SCRL_RIGHT
  #define MOUSE_SCROLL_RIGHT SCRL_LEFT
  #define NATURAL_SCROLLING_FACTOR -1
#else
  #define MOUSE_SCROLL_UP    SCRL_UP
  #define MOUSE_SCROLL_DOWN  SCRL_DOWN
  #define MOUSE_SCROLL_LEFT  SCRL_LEFT
  #define MOUSE_SCROLL_RIGHT SCRL_RIGHT
  #define NATURAL_SCROLLING_FACTOR 1
#endif

//
// MOUSE_MOTION_DELAY defines how long to wait (milliseconds) before starting
// to move the mouse pointer.
//
#ifndef MOUSE_MOTION_DELAY
#define MOUSE_MOTION_DELAY 0
#endif

//
// MOUSE_MOTION_ACCELERATION_EXPONENT sets how the mouse pointer accelerates:
//
// acceleration exponent 0: uniform speed
// acceleration exponent 1: uniform acceleration
// acceleration exponent 2: uniform jerk
//
#ifndef MOUSE_MOTION_ACCELERATION_EXPONENT
#define MOUSE_MOTION_ACCELERATION_EXPONENT 1
#endif

//
// MOUSE_MOTION_TIME_TO_MAXIMUM_SPEED defines how long to wait (milliseconds)
// before the mouse pointer speed is suddenly boosted to the maximum value.
//
#ifndef MOUSE_MOTION_TIME_TO_MAXIMUM_SPEED
#define MOUSE_MOTION_TIME_TO_MAXIMUM_SPEED 300
#endif

//
// MOUSE_MOTION_MAXIMUM_SPEED defines how quickly the mouse pointer can move.
//
#ifndef MOUSE_MOTION_MAXIMUM_SPEED
#define MOUSE_MOTION_MAXIMUM_SPEED 200
#endif

//
// MOUSE_SCROLL_DELAY defines how long to wait (milliseconds) before starting
// to move the mouse pointer.
//
#ifndef MOUSE_SCROLL_DELAY
#define MOUSE_SCROLL_DELAY 0
#endif

//
// MOUSE_SCROLL_ACCELERATION_EXPONENT sets how the mouse pointer accelerates:
//
// acceleration exponent 0: uniform speed
// acceleration exponent 1: uniform acceleration
// acceleration exponent 2: uniform jerk
//
#ifndef MOUSE_SCROLL_ACCELERATION_EXPONENT
#define MOUSE_SCROLL_ACCELERATION_EXPONENT 0
#endif

//
// MOUSE_SCROLL_TIME_TO_MAXIMUM_SPEED defines how long to wait (milliseconds)
// before the mouse pointer speed is suddenly boosted to the maximum value.
//
#ifndef MOUSE_SCROLL_TIME_TO_MAXIMUM_SPEED
#define MOUSE_SCROLL_TIME_TO_MAXIMUM_SPEED 300
#endif

//
// MOUSE_SCROLL_MAXIMUM_SPEED defines how quickly the mouse wheel can scroll.
//
#ifndef MOUSE_SCROLL_MAXIMUM_SPEED
#define MOUSE_SCROLL_MAXIMUM_SPEED 10
#endif

//
// THUMB_MOUSE_SCROLL_SPEED applies to base layer's scroll up/down keys.
//
#ifndef THUMB_MOUSE_SCROLL_SPEED
#define THUMB_MOUSE_SCROLL_SPEED 33
#endif

#define thums_up   msc MOVE_Y(THUMB_MOUSE_SCROLL_SPEED * NATURAL_SCROLLING_FACTOR)
#define thums_down msc MOVE_Y(THUMB_MOUSE_SCROLL_SPEED * NATURAL_SCROLLING_FACTOR * -1)

//
// MOUSE_MOTION_SCALER_SLOW sets parameters for the &zip_xy_scaler input processor:
// https://zmk.dev/docs/keymaps/input-processors/scaler
//
#ifndef MOUSE_MOTION_SCALER_SLOW
#define MOUSE_MOTION_SCALER_SLOW 1 12
#endif

//
// MOUSE_MOTION_SCALER_FAST sets parameters for the &zip_xy_scaler input processor:
// https://zmk.dev/docs/keymaps/input-processors/scaler
//
#ifndef MOUSE_MOTION_SCALER_FAST
#define MOUSE_MOTION_SCALER_FAST 4 1
#endif

//
// MOUSE_MOTION_SCALER_WARP sets parameters for the &zip_xy_scaler input processor:
// https://zmk.dev/docs/keymaps/input-processors/scaler
//
#ifndef MOUSE_MOTION_SCALER_WARP
#define MOUSE_MOTION_SCALER_WARP 12 1
#endif

//
// MOUSE_SCROLL_SCALER_SLOW sets parameters for the &zip_scroll_scaling_processor:
// https://zmk.dev/docs/keymaps/input-processors/scaler
//
#ifndef MOUSE_SCROLL_SCALER_SLOW
#define MOUSE_SCROLL_SCALER_SLOW 1 9
#endif

//
// MOUSE_SCROLL_SCALER_FAST sets parameters for the &zip_scroll_scaling_processor:
// https://zmk.dev/docs/keymaps/input-processors/scaler
//
#ifndef MOUSE_SCROLL_SCALER_FAST
#define MOUSE_SCROLL_SCALER_FAST 3 1
#endif

//
// MOUSE_SCROLL_SCALER_WARP sets parameters for the &zip_scroll_scaling_processor:
// https://zmk.dev/docs/keymaps/input-processors/scaler
//
#ifndef MOUSE_SCROLL_SCALER_WARP
#define MOUSE_SCROLL_SCALER_WARP 9 1
#endif
#ifdef ENABLE_MOUSE_KEYS
  // ==== MOUSE-KEY <section begins> ====
  #define ZMK_POINTING_DEFAULT_MOVE_VAL MOUSE_MOTION_MAXIMUM_SPEED
  #define ZMK_POINTING_DEFAULT_SCRL_VAL MOUSE_SCROLL_MAXIMUM_SPEED
  #include <dt-bindings/zmk/pointing.h>
  &mmv {
    delay-ms = <MOUSE_MOTION_DELAY>;
    acceleration-exponent = <MOUSE_MOTION_ACCELERATION_EXPONENT>;
    time-to-max-speed-ms = <MOUSE_MOTION_TIME_TO_MAXIMUM_SPEED>;
  };
  &msc {
    delay-ms = <MOUSE_SCROLL_DELAY>;
    acceleration-exponent = <MOUSE_SCROLL_ACCELERATION_EXPONENT>;
    time-to-max-speed-ms = <MOUSE_SCROLL_TIME_TO_MAXIMUM_SPEED>;
  };
  //
  // Scaling for mouse movement, based on @caksoylar's example:
  // https://github.com/caksoylar/zmk-config/commit/0020c23c544cd7111013f0114609d1fb90e0e475
  //
  #include <input/processors.dtsi>
  &mmv_input_listener {
    #ifdef LAYER_Mouse_slow
    slow {
      layers = <LAYER_Mouse_slow>;
      input-processors = <&zip_xy_scaler MOUSE_MOTION_SCALER_SLOW>;
    };
    #endif
    #ifdef LAYER_Mouse_warp
    warp {
      layers = <LAYER_Mouse_warp>;
      input-processors = <&zip_xy_scaler MOUSE_MOTION_SCALER_WARP>;
    };
    #endif
    #ifdef LAYER_Mouse_fast
    fast {
      layers = <LAYER_Mouse_fast>;
      input-processors = <&zip_xy_scaler MOUSE_MOTION_SCALER_FAST>;
    };
    #endif
  };
  //
  // Scaling for mouse scrolling, based on @caksoylar's example:
  // https://github.com/caksoylar/zmk-config/commit/e35ee2f08788927683df7bbdd7fc73434473886e
  //
  #include <zephyr/dt-bindings/input/input-event-codes.h>
  / {
    input_processors {
      zip_scroll_scaling_processor: zip_scroll_scaling_processor {
        compatible = "zmk,input-processor-scaler";
        #input-processor-cells = <2>;
        type = <INPUT_EV_REL>;
        codes = <INPUT_REL_WHEEL INPUT_REL_HWHEEL>;
        track-remainders;
      };
    };
  };
  &msc_input_listener {
    #ifdef LAYER_Mouse_slow
    slow {
      layers = <LAYER_Mouse_slow>;
      input-processors = <&zip_scroll_scaling_processor MOUSE_SCROLL_SCALER_SLOW>;
    };
    #endif
    #ifdef LAYER_Mouse_warp
    warp {
      layers = <LAYER_Mouse_warp>;
      input-processors = <&zip_scroll_scaling_processor MOUSE_SCROLL_SCALER_WARP>;
    };
    #endif
    #ifdef LAYER_Mouse_fast
    fast {
      layers = <LAYER_Mouse_fast>;
      input-processors = <&zip_scroll_scaling_processor MOUSE_SCROLL_SCALER_FAST>;
    };
    #endif
  };
  // ==== MOUSE-KEY <section ends> =====
#else
  #define mkp none
  #define mmv none
  #define msc none
  #define LCLK
  #define MCLK
  #define RCLK
  #define MB1
  #define MB2
  #define MB3
  #define MB4
  #define MB5
  #define MOVE_UP
  #define MOVE_DOWN
  #define MOVE_LEFT
  #define MOVE_RIGHT
  #define SCRL_UP
  #define SCRL_DOWN
  #define SCRL_LEFT
  #define SCRL_RIGHT
#endif

